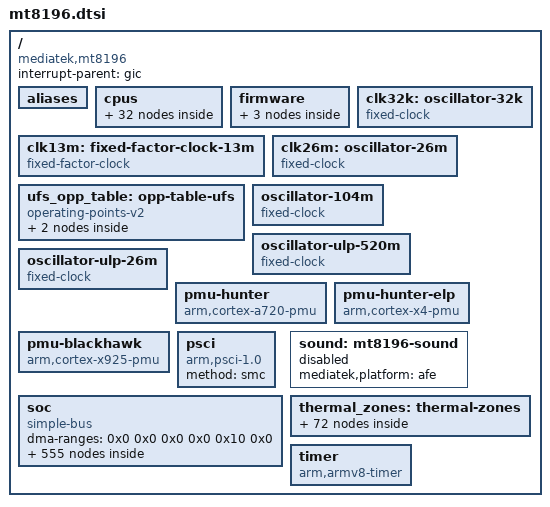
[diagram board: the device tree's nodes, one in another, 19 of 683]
// SPDX-License-Identifier: (GPL-2.0 OR MIT)
/*
 * Copyright (c) 2024 MediaTek Inc.
 * Copyright (c) 2025 Collabora Ltd
 *                    AngeloGioacchino Del Regno <angelogioacchino.delregno@collabora.com>
 */

/dts-v1/;
#include <dt-bindings/clock/mediatek,mt8196-clock.h>
#include <dt-bindings/reset/mediatek,mt8196-resets.h>
#include <dt-bindings/interrupt-controller/arm-gic.h>
#include <dt-bindings/interrupt-controller/irq.h>
#include <dt-bindings/phy/phy.h>
#include <dt-bindings/power/mediatek,mt8196-power.h>
#include <dt-bindings/reset/mediatek,mt8196-resets.h>
#include <dt-bindings/thermal/mediatek,lvts-thermal.h>
#include "mt8196-gce.h"
#include "mt8196-pinfunc.h"

/ {
	compatible = "mediatek,mt8196";
	interrupt-parent = <&gic>;
	#address-cells = <2>;
	#size-cells = <2>;

	aliases {
		blender0 = &ovl0_blender0;
		blender1 = &ovl0_blender1;
		blender2 = &ovl0_blender2;
		blender3 = &ovl0_blender3;
		blender4 = &ovl0_blender4;
		blender5 = &ovl0_blender5;
		blender6 = &ovl0_blender6;
		blender7 = &ovl0_blender7;
		blender8 = &ovl0_blender8;
		blender9 = &ovl0_blender9;
		blender10 = &ovl1_blender0;
		blender11 = &ovl1_blender1;
		blender12 = &ovl1_blender2;
		blender13 = &ovl1_blender3;
		blender14 = &ovl1_blender4;
		blender15 = &ovl1_blender5;
		blender16 = &ovl1_blender6;
		blender17 = &ovl1_blender7;
		blender18 = &ovl1_blender8;
		blender19 = &ovl1_blender9;
		ccorr0 = &ccorr0;
		ccorr1 = &ccorr1;
		ccorr2 = &ccorr2;
		ccorr3 = &ccorr3;
		dither0 = &dither0;
		dither1 = &dither1;
		dither2 = &disp1_dither2;
		dp-intf0 = &dp_intf0;
		dp-intf1 = &dp_intf1;
		dsc0 = &dsc0;
		dsc1 = &dsc1;
		dvo0 = &dvo0;
		exdma2 = &ovl0_exdma2;
		exdma3 = &ovl0_exdma3;
		exdma4 = &ovl0_exdma4;
		exdma5 = &ovl0_exdma5;
		exdma6 = &ovl0_exdma6;
		exdma7 = &ovl0_exdma7;
		exdma8 = &ovl0_exdma8;
		exdma9 = &ovl0_exdma9;
		exdma12 = &ovl1_exdma2;
		exdma13 = &ovl1_exdma3;
		exdma14 = &ovl1_exdma4;
		exdma15 = &ovl1_exdma5;
		exdma16 = &ovl1_exdma6;
		exdma17 = &ovl1_exdma7;
		exdma18 = &ovl1_exdma8;
		exdma19 = &ovl1_exdma9;
		gamma0 = &gamma0;
		gamma1 = &gamma1;
		i2c0 = &i2c0;
		i2c1 = &i2c1;
		i2c2 = &i2c2;
		i2c3 = &i2c3;
		i2c4 = &i2c4;
		i2c5 = &i2c5;
		i2c6 = &i2c6;
		i2c7 = &i2c7;
		i2c8 = &i2c8;
		i2c9 = &i2c9;
		i2c10 = &i2c10;
		i2c11 = &i2c11;
		i2c12 = &i2c12;
		i2c13 = &i2c13;
		i2c14 = &i2c14;
		mmc1 = &mmc1;
		mmc2 = &mmc2;
		mutex0 = &disp0_mutex;
		mutex1 = &disp1_mutex;
		mutex2 = &ovl0_mutex;
		mutex3 = &ovl1_mutex;
		outproc0 = &ovl0_outproc0;
		outproc1 = &ovl0_outproc1;
		outproc2 = &ovl0_outproc2;
		outproc3 = &ovl0_outproc3;
		outproc4 = &ovl0_outproc4;
		outproc5 = &ovl0_outproc5;
		outproc6 = &ovl1_outproc0;
		outproc7 = &ovl1_outproc1;
		outproc8 = &ovl1_outproc2;
		outproc9 = &ovl1_outproc3;
		outproc10 = &ovl1_outproc4;
		outproc11 = &ovl1_outproc5;
		postmask0 = &postmask0;
		postmask1 = &postmask1;
		resizer0 = &mdp_rsz0;
		resizer1 = &mdp_rsz1;
		resizer2 = &ovl0_rsz0;
		resizer4 = &ovl1_rsz0;
		spmi0 = &spmi0;
		spmi1 = &spmi1;
		tdshp0 = &tdshp0;
		tdshp1 = &tdshp1;
	};

	cpus {
		#address-cells = <1>;
		#size-cells = <0>;

		cpu0: cpu@0 {
			device_type = "cpu";
			compatible = "arm,cortex-a720";
			reg = <0x000>;
			enable-method = "psci";
			capacity-dmips-mhz = <714>;
			clock-frequency = <2100000000>;
			cpu-idle-states = <&cpuoff_l &clusteroff_l &s2idle>;
			performance-domains = <&performance 0>;
			i-cache-size = <65536>;
			i-cache-line-size = <64>;
			i-cache-sets = <256>;
			d-cache-size = <65536>;
			d-cache-line-size = <64>;
			d-cache-sets = <256>;
			next-level-cache = <&l2_0>;
			#cooling-cells = <2>;
		};

		cpu1: cpu@100 {
			device_type = "cpu";
			compatible = "arm,cortex-a720";
			reg = <0x100>;
			enable-method = "psci";
			capacity-dmips-mhz = <714>;
			clock-frequency = <2100000000>;
			cpu-idle-states = <&cpuoff_l &clusteroff_l &s2idle>;
			performance-domains = <&performance 0>;
			i-cache-size = <65536>;
			i-cache-line-size = <64>;
			i-cache-sets = <256>;
			d-cache-size = <65536>;
			d-cache-line-size = <64>;
			d-cache-sets = <256>;
			next-level-cache = <&l2_0>;
			#cooling-cells = <2>;
		};

		cpu2: cpu@200 {
			device_type = "cpu";
			compatible = "arm,cortex-a720";
			reg = <0x200>;
			enable-method = "psci";
			capacity-dmips-mhz = <714>;
			clock-frequency = <2100000000>;
			cpu-idle-states = <&cpuoff_l &clusteroff_l &s2idle>;
			performance-domains = <&performance 0>;
			i-cache-size = <65536>;
			i-cache-line-size = <64>;
			i-cache-sets = <256>;
			d-cache-size = <65536>;
			d-cache-line-size = <64>;
			d-cache-sets = <256>;
			next-level-cache = <&l2_0>;
			#cooling-cells = <2>;
		};

		cpu3: cpu@300 {
			device_type = "cpu";
			compatible = "arm,cortex-a720";
			reg = <0x300>;
			enable-method = "psci";
			capacity-dmips-mhz = <714>;
			clock-frequency = <2100000000>;
			cpu-idle-states = <&cpuoff_l &clusteroff_l &s2idle>;
			performance-domains = <&performance 0>;
			i-cache-size = <65536>;
			i-cache-line-size = <64>;
			i-cache-sets = <256>;
			d-cache-size = <65536>;
			d-cache-line-size = <64>;
			d-cache-sets = <256>;
			next-level-cache = <&l2_0>;
			#cooling-cells = <2>;
		};

		cpu4: cpu@400 {
			device_type = "cpu";
			compatible = "arm,cortex-x4";
			reg = <0x400>;
			enable-method = "psci";
			capacity-dmips-mhz = <835>;
			clock-frequency = <2800000000>;
			cpu-idle-states = <&cpuoff_m &clusteroff_m &s2idle>;
			performance-domains = <&performance 1>;
			i-cache-size = <65536>;
			i-cache-line-size = <64>;
			i-cache-sets = <256>;
			d-cache-size = <65536>;
			d-cache-line-size = <64>;
			d-cache-sets = <256>;
			next-level-cache = <&l2_1>;
			#cooling-cells = <2>;
		};

		cpu5: cpu@500 {
			device_type = "cpu";
			compatible = "arm,cortex-x4";
			reg = <0x500>;
			enable-method = "psci";
			capacity-dmips-mhz = <835>;
			clock-frequency = <2800000000>;
			cpu-idle-states = <&cpuoff_m &clusteroff_m &s2idle>;
			performance-domains = <&performance 1>;
			i-cache-size = <65536>;
			i-cache-line-size = <64>;
			i-cache-sets = <256>;
			d-cache-size = <65536>;
			d-cache-line-size = <64>;
			d-cache-sets = <256>;
			next-level-cache = <&l2_1>;
			#cooling-cells = <2>;
		};

		cpu6: cpu@600 {
			device_type = "cpu";
			compatible = "arm,cortex-x4";
			reg = <0x600>;
			enable-method = "psci";
			capacity-dmips-mhz = <835>;
			clock-frequency = <2800000000>;
			cpu-idle-states = <&cpuoff_m &clusteroff_m &s2idle>;
			performance-domains = <&performance 1>;
			i-cache-size = <65536>;
			i-cache-line-size = <64>;
			i-cache-sets = <256>;
			d-cache-size = <65536>;
			d-cache-line-size = <64>;
			d-cache-sets = <256>;
			next-level-cache = <&l2_1>;
			#cooling-cells = <2>;
		};

		cpu7: cpu@700 {
			device_type = "cpu";
			compatible = "arm,cortex-x925";
			reg = <0x700>;
			enable-method = "psci";
			capacity-dmips-mhz = <1024>;
			clock-frequency = <3600000000>;
			cpu-idle-states = <&cpuoff_b &clusteroff_b &s2idle>;
			performance-domains = <&performance 2>;
			i-cache-size = <65536>;
			i-cache-line-size = <64>;
			i-cache-sets = <256>;
			d-cache-size = <65536>;
			d-cache-line-size = <64>;
			d-cache-sets = <256>;
			next-level-cache = <&l2_2>;
			#cooling-cells = <2>;
		};

		cpu-map {
			cluster0 {
				core0 {
					cpu = <&cpu0>;
				};
				core1 {
					cpu = <&cpu1>;
				};
				core2 {
					cpu = <&cpu2>;
				};
				core3 {
					cpu = <&cpu3>;
				};
			};

			cluster1 {
				core0 {
					cpu = <&cpu4>;
				};
				core1 {
					cpu = <&cpu5>;
				};
				core2 {
					cpu = <&cpu6>;
				};
			};

			cluster2 {
				core0 {
					cpu = <&cpu7>;
				};
			};
		};

		idle-states {
			entry-method = "psci";

			cpuoff_l: cpuoff-l {
				compatible = "arm,idle-state";
				arm,psci-suspend-param = <0x00010000>;
				local-timer-stop;
				entry-latency-us = <97>;
				exit-latency-us = <252>;
				min-residency-us = <6710>;
			};

			cpuoff_m: cpuoff-m {
				compatible = "arm,idle-state";
				arm,psci-suspend-param = <0x00010000>;
				local-timer-stop;
				entry-latency-us = <53>;
				exit-latency-us = <143>;
				min-residency-us = <2120>;
			};

			cpuoff_b: cpuoff-b {
				compatible = "arm,idle-state";
				arm,psci-suspend-param = <0x00010000>;
				local-timer-stop;
				entry-latency-us = <40>;
				exit-latency-us = <107>;
				min-residency-us = <2580>;
			};

			clusteroff_l: clusteroff-l {
				compatible = "arm,idle-state";
				arm,psci-suspend-param = <0x01010001>;
				local-timer-stop;
				entry-latency-us = <109>;
				exit-latency-us = <325>;
				min-residency-us = <6710>;
			};

			clusteroff_m: clusteroff-m {
				compatible = "arm,idle-state";
				arm,psci-suspend-param = <0x01010001>;
				local-timer-stop;
				entry-latency-us = <59>;
				exit-latency-us = <188>;
				min-residency-us = <2120>;
			};

			clusteroff_b: clusteroff-b {
				compatible = "arm,idle-state";
				arm,psci-suspend-param = <0x01010001>;
				local-timer-stop;
				entry-latency-us = <43>;
				exit-latency-us = <138>;
				min-residency-us = <2580>;
			};

			s2idle: s2idle {
				compatible = "arm,idle-state";
				arm,psci-suspend-param = <0x020180ff>;
				local-timer-stop;
				entry-latency-us = <10000>;
				exit-latency-us = <10000>;
				min-residency-us = <6400000>;
			};
		};

		l2_0: l2-cache0 {
			compatible = "cache";
			cache-level = <2>;
			cache-size = <524288>;
			cache-line-size = <64>;
			cache-sets = <2048>;
			next-level-cache = <&l3_0>;
			cache-unified;
		};

		l2_1: l2-cache1 {
			compatible = "cache";
			cache-level = <2>;
			cache-size = <1048576>;
			cache-line-size = <64>;
			cache-sets = <4096>;
			next-level-cache = <&l3_0>;
			cache-unified;
		};

		l2_2: l2-cache2 {
			compatible = "cache";
			cache-level = <2>;
			cache-size = <2097152>;
			cache-line-size = <64>;
			cache-sets = <8192>;
			next-level-cache = <&l3_0>;
			cache-unified;
		};

		l3_0: l3-cache {
			compatible = "cache";
			cache-level = <3>;
			cache-size = <12582912>;
			cache-line-size = <64>;
			cache-sets = <49152>;
			cache-unified;
		};
	};

	firmware {
		optee {
			compatible = "linaro,optee-tz";
			method = "smc";
			interrupts-extended = <&gic GIC_SPI 955 IRQ_TYPE_LEVEL_HIGH 0>;
		};

		scmi {
			compatible = "arm,scmi";
			mboxes = <&tinysys_mbox_tx 0>, <&tinysys_mbox_rx 0>;
			mbox-names = "tx", "rx";
			shmem = <&scmi_tx_shmem>, <&scmi_rx_shmem>;
			#address-cells = <1>;
			#size-cells = <0>;

			scmi_tinysys: protocol@80 {
				reg = <0x80>;
			};
		};
	};

	clk13m: fixed-factor-clock-13m {
		compatible = "fixed-factor-clock";
		#clock-cells = <0>;
		clocks = <&clk26m>;
		clock-div = <2>;
		clock-mult = <1>;
		clock-output-names = "clk13m";
	};

	clk32k: oscillator-32k {
		compatible = "fixed-clock";
		#clock-cells = <0>;
		clock-frequency = <32000>;
		clock-output-names = "clk32k";
	};

	/* clk26m/104m may be turned off by firmware for deep sleep */
	clk26m: oscillator-26m {
		compatible = "fixed-clock";
		#clock-cells = <0>;
		clock-frequency = <26000000>;
		clock-output-names = "clk26m";
	};

	ufs_opp_table: opp-table-ufs {
		compatible = "operating-points-v2";

		opp-499200000 {
			opp-hz = /bits/ 64 <499200000>, /bits/ 64 <0>,
				 /bits/ 64 <0>, /bits/ 64 <0>, /bits/ 64 <0>,
				 /bits/ 64 <0>, /bits/ 64 <0>, /bits/ 64 <0>,
				 /bits/ 64 <0>, /bits/ 64 <0>, /bits/ 64 <0>,
				 /bits/ 64 <0>, /bits/ 64 <0>, /bits/ 64 <0>,
				 /bits/ 64 <0>, /bits/ 64 <0>;
		};

		opp-273000000 {
			opp-hz = /bits/ 64 <273000000>, /bits/ 64 <0>,
				 /bits/ 64 <0>, /bits/ 64 <0>, /bits/ 64 <0>,
				 /bits/ 64 <0>, /bits/ 64 <0>, /bits/ 64 <0>,
				 /bits/ 64 <0>, /bits/ 64 <0>, /bits/ 64 <0>,
				 /bits/ 64 <0>, /bits/ 64 <0>, /bits/ 64 <0>,
				 /bits/ 64 <0>, /bits/ 64 <0>;
		};
	};

	oscillator-104m {
		compatible = "fixed-clock";
		#clock-cells = <0>;
		clock-frequency = <104000000>;
		clock-output-names = "clk104m";
	};

	/* Ultra Low Power Oscillators used in deeper sleep states */
	oscillator-ulp-520m {
		compatible = "fixed-clock";
		#clock-cells = <0>;
		clock-frequency = <520000000>;
		clock-output-names = "ulposc";
	};

	oscillator-ulp-26m {
		compatible = "fixed-clock";
		#clock-cells = <0>;
		clock-frequency = <26000000>;
		clock-output-names = "ulposc3";
	};

	pmu-hunter {
		compatible = "arm,cortex-a720-pmu";
		interrupt-parent = <&gic>;
		interrupts = <GIC_PPI 7 IRQ_TYPE_LEVEL_HIGH &ppi_cluster0>;
	};

	pmu-hunter-elp {
		compatible = "arm,cortex-x4-pmu";
		interrupt-parent = <&gic>;
		interrupts = <GIC_PPI 7 IRQ_TYPE_LEVEL_HIGH &ppi_cluster1>;
	};

	pmu-blackhawk {
		compatible = "arm,cortex-x925-pmu";
		interrupt-parent = <&gic>;
		interrupts = <GIC_PPI 7 IRQ_TYPE_LEVEL_HIGH &ppi_cluster2>;
	};

	psci {
		compatible = "arm,psci-1.0";
		method = "smc";
	};

	soc {
		compatible = "simple-bus";
		#address-cells = <2>;
		#size-cells = <2>;
		ranges;
		dma-ranges = <0x0 0x0 0x0 0x0 0x10 0x0>;

		performance: performance-controller@c220400 {
			compatible = "mediatek,mt8196-cpufreq-hw";
			reg = <0 0xc220400 0 0x20>, <0 0xc2c0f20 0 0x120>,
			      <0 0xc2c1040 0 0x120>, <0 0xc2c1160 0 0x120>;
			#performance-domain-cells = <1>;
		};

		lvts_mcu: thermal-sensor@c230000 {
			compatible = "mediatek,mt8196-lvts-mcu";
			reg = <0 0x0c230000 0 0x1000>;
			interrupts = <GIC_SPI 104 IRQ_TYPE_LEVEL_HIGH 0>;
			clocks = <&clk26m>;
			nvmem-cells = <&lvts_efuse_data1 &lvts_efuse_data2
				       &lvts_efuse_data3 &lvts_efuse_data4>;
			nvmem-cell-names = "lvts-calib-data-1","lvts-calib-data-2",
					   "lvts-calib-data-3","lvts-calib-data-4";
			#thermal-sensor-cells = <1>;
		};

		gic: interrupt-controller@c400000 {
			compatible = "arm,gic-v3";
			reg = <0 0xc400000 0 0x40000>, <0 0xc440000 0 0x200000>;
			interrupt-parent = <&gic>;
			interrupts = <GIC_PPI 9 IRQ_TYPE_LEVEL_HIGH 0>;
			interrupt-controller;
			#interrupt-cells = <4>;
			#redistributor-regions = <1>;

			ppi-partitions {
				ppi_cluster0: interrupt-partition-0 {
					affinity = <&cpu0 &cpu1 &cpu2 &cpu3>;
				};

				ppi_cluster1: interrupt-partition-1 {
					affinity = <&cpu4 &cpu5 &cpu6>;
				};

				ppi_cluster2: interrupt-partition-2 {
					affinity = <&cpu7>;
				};
			};
		};

		topckgen: clock-controller@10000000 {
			compatible = "mediatek,mt8196-topckgen", "syscon";
			reg = <0 0x10000000 0 0x800>;
			mediatek,hardware-voter = <&scp_hwv>;
			#clock-cells = <1>;
		};

		apmixedsys: clock-controller@10000800 {
			compatible = "mediatek,mt8196-apmixedsys", "syscon";
			reg = <0 0x10000800 0 0x1000>;
			#clock-cells = <1>;
		};

		topckgen_gp2: clock-controller@1000c000 {
			compatible = "mediatek,mt8196-topckgen-gp2", "syscon";
			reg = <0 0x1000c000 0 0x800>;
			mediatek,hardware-voter = <&hfrpsys_hwv>;
			#clock-cells = <1>;
		};

		apmixedsys_gp2: clock-controller@1000c800 {
			compatible = "mediatek,mt8196-apmixedsys-gp2", "syscon";
			reg = <0 0x1000c800 0 0x1000>;
			#clock-cells = <1>;
		};

		infra_bus: bus@1002c000 {
			compatible = "simple-bus";
			reg = <0 0x1002c000 0 0x1000>;
			#address-cells = <2>;
			#size-cells = <2>;
			ranges;
			#access-controller-cells = <0>;
		};

		pio: pinctrl@1002d000 {
			compatible = "mediatek,mt8196-pinctrl";
			reg = <0 0x1002d000 0 0x1000>, <0 0x12000000 0 0x1000>,
			      <0 0x12020000 0 0x1000>, <0 0x12040000 0 0x1000>,
			      <0 0x12060000 0 0x1000>, <0 0x12820000 0 0x1000>,
			      <0 0x12840000 0 0x1000>, <0 0x12860000 0 0x1000>,
			      <0 0x13000000 0 0x1000>, <0 0x13020000 0 0x1000>,
			      <0 0x13040000 0 0x1000>, <0 0x130f0000 0 0x1000>,
			      <0 0x13110000 0 0x1000>, <0 0x13800000 0 0x1000>,
			      <0 0x13820000 0 0x1000>, <0 0x13860000 0 0x1000>,
			      <0 0x12080000 0 0x1000>, <0 0x12880000 0 0x1000>,
			      <0 0x13080000 0 0x1000>, <0 0x13880000 0 0x1000>,
			      <0 0x1c54a000 0 0x1000>;
			reg-names = "base", "rt", "rm1", "rm2", "rb", "bm1",
				    "bm2", "bm3", "lt", "lm1", "lm2", "lb1",
				    "lb2", "tm1", "tm2", "tm3", "eint0",
				    "eint1", "eint2", "eint3", "eint4";
			gpio-controller;
			#gpio-cells = <2>;
			gpio-ranges = <&pio 0 0 271>;
			interrupt-controller;
			interrupts = <GIC_SPI 396 IRQ_TYPE_LEVEL_HIGH 0>;
			#interrupt-cells = <2>;
			mediatek,rsel-resistance-in-si-unit;
		};

		i2c5: i2c@120a0000 {
			compatible = "mediatek,mt8196-i2c", "mediatek,mt8188-i2c";
			reg = <0 0x120a0000 0 0x20000>, <0 0x16400000 0 0x10000>;
			interrupts = <GIC_SPI 341 IRQ_TYPE_LEVEL_HIGH 0>;
			clocks = <&imp_iic_wrap_east CLK_IMPE_I2C5>,
				 <&pericfg_ao CLK_PERI_AO_AP_DMA_X32W_BCLK>;
			clock-names = "main", "dma";
			clock-div = <1>;
			#address-cells = <1>;
			#size-cells = <0>;
			status = "disabled";
		};

		imp_iic_wrap_east: clock-controller@120c0000 {
			compatible = "mediatek,mt8196-imp-iic-wrap-e", "syscon";
			reg = <0 0x120c0000 0 0x1000>;
			#clock-cells = <1>;
		};

		edp_phy: phy@130a0000 {
			compatible = "mediatek,mt8196-edp-phy";
			reg = <0 0x130a0000 0 0x1500>;
			#phy-cells = <0>;
			status = "disabled";

			nvmem-cells = <&edp_glb_bias_trim>, <&edp_clktx_impsel>,
				      <&edp_imp_ln0_pmos>, <&edp_imp_ln0_nmos>,
				      <&edp_imp_ln1_pmos>, <&edp_imp_ln1_nmos>,
				      <&edp_imp_ln2_pmos>, <&edp_imp_ln2_nmos>,
				      <&edp_imp_ln3_pmos>, <&edp_imp_ln3_nmos>;
			nvmem-cell-names = "rbias-trim", "impedance-txclk",
					   "impedance-lane0p", "impedance-lane0n",
					   "impedance-lane1p", "impedance-lane1n",
					   "impedance-lane2p", "impedance-lane2n",
					   "impedance-lane3p", "impedance-lane3n";

			power-domains = <&hpm_hwv MT8196_POWER_DOMAIN_DISP_EDPTX_DORMANT>;
		};

		mipi_tx_config0: dsi-phy@130b0000 {
			compatible = "mediatek,mt8196-mipi-tx";
			reg = <0 0x130b0000 0 0x1000>;
			clocks = <&clk26m>;
			clock-output-names = "mipi_tx0_pll";
			power-domains = <&hpm_hwv MT8196_POWER_DOMAIN_DSI_PHY0>;
			#clock-cells = <0>;
			#phy-cells = <0>;
			status = "disabled";
		};

		mipi_tx_config1: dsi-phy@130c0000 {
			compatible = "mediatek,mt8196-mipi-tx";
			reg = <0 0x130c0000 0 0x1000>;
			clocks = <&clk26m>;
			clock-output-names = "mipi_tx1_pll";
			power-domains = <&hpm_hwv MT8196_POWER_DOMAIN_DSI_PHY1>;
			#clock-cells = <0>;
			#phy-cells = <0>;
			status = "disabled";
		};

		mipi_tx_config2: dsi-phy@130d0000 {
			compatible = "mediatek,mt8196-mipi-tx";
			reg = <0 0x130d0000 0 0x1000>;
			clocks = <&clk26m>;
			clock-output-names = "mipi_tx2_pll";
			power-domains = <&hpm_hwv MT8196_POWER_DOMAIN_DSI_PHY2>;
			#clock-cells = <0>;
			#phy-cells = <0>;
			status = "disabled";
		};

		i2c0: i2c@13130000 {
			compatible = "mediatek,mt8196-i2c", "mediatek,mt8188-i2c";
			reg = <0 0x13130000 0 0x20000>, <0 0x16370000 0 0x10000>;
			interrupts = <GIC_SPI 342 IRQ_TYPE_LEVEL_HIGH 0>;
			clocks = <&imp_iic_wrap_west CLK_IMPW_I2C0>,
				 <&pericfg_ao CLK_PERI_AO_AP_DMA_X32W_BCLK>;
			clock-names = "main", "dma";
			clock-div = <1>;
			#address-cells = <1>;
			#size-cells = <0>;
			status = "disabled";
		};

		i2c3: i2c@13150000 {
			compatible = "mediatek,mt8196-i2c", "mediatek,mt8188-i2c";
			reg = <0 0x13150000 0 0x20000>, <0 0x163c0000 0 0x10000>;
			interrupts = <GIC_SPI 340 IRQ_TYPE_LEVEL_HIGH 0>;
			clocks = <&imp_iic_wrap_west CLK_IMPW_I2C3>,
				 <&pericfg_ao CLK_PERI_AO_AP_DMA_X32W_BCLK>;
			clock-names = "main", "dma";
			clock-div = <1>;
			#address-cells = <1>;
			#size-cells = <0>;
			status = "disabled";
		};

		i2c6: i2c@13170000 {
			compatible = "mediatek,mt8196-i2c", "mediatek,mt8188-i2c";
			reg = <0 0x13170000 0 0x20000>, <0 0x16410000 0 0x10000>;
			interrupts = <GIC_SPI 343 IRQ_TYPE_LEVEL_HIGH 0>;
			clocks = <&imp_iic_wrap_west CLK_IMPW_I2C6>,
				 <&pericfg_ao CLK_PERI_AO_AP_DMA_X32W_BCLK>;
			clock-names = "main", "dma";
			clock-div = <1>;
			#address-cells = <1>;
			#size-cells = <0>;
			status = "disabled";
		};

		i2c10: i2c@13190000 {
			compatible = "mediatek,mt8196-i2c", "mediatek,mt8188-i2c";
			reg = <0 0x13190000 0 0x20000>,
			      <0 0x164b0000 0 0x10000>;
			interrupts = <GIC_SPI 344 IRQ_TYPE_LEVEL_HIGH 0>;
			clocks = <&imp_iic_wrap_west CLK_IMPW_I2C10>,
				 <&pericfg_ao CLK_PERI_AO_AP_DMA_X32W_BCLK>;
			clock-names = "main", "dma";
			clock-div = <1>;
			#address-cells = <1>;
			#size-cells = <0>;
			status = "disabled";
		};

		imp_iic_wrap_west: clock-controller@131b0000 {
			compatible = "mediatek,mt8196-imp-iic-wrap-w", "syscon";
			reg = <0 0x131b0000 0 0x1000>;
			#clock-cells = <1>;
		};

		efuse: efuse@13260000 {
			compatible = "mediatek,mt8196-efuse", "mediatek,efuse";
			reg = <0 0x13260000 0 0x1000>;
			#address-cells = <1>;
			#size-cells = <1>;

			edp_clktx_impsel: edp-dphy-impedance-clk@1b9 {
				reg = <0x1b9 0x1>;
				bits = <1 4>;
			};

			edp_imp_ln3_nmos: edp-dphy-imp-ln3-nmos@1c0,1 {
				reg = <0x1c0 0x1>;
				bits = <0 4>;
			};

			edp_imp_ln3_pmos: edp-dphy-imp-ln3-pmos@1c0,2 {
				reg = <0x1c0 0x1>;
				bits = <4 4>;
			};

			edp_imp_ln2_nmos: edp-dphy-imp-ln2-nmos@1c1,1 {
				reg = <0x1c1 0x1>;
				bits = <0 4>;
			};

			edp_imp_ln2_pmos: edp-dphy-imp-ln2-pmos@1c1,2 {
				reg = <0x1c1 0x1>;
				bits = <4 4>;
			};

			edp_imp_ln1_nmos: edp-dphy-imp-ln1-nmos@1c2,1 {
				reg = <0x1c2 0x1>;
				bits = <0 4>;
			};

			edp_imp_ln1_pmos: edp-dphy-imp-ln1-pmos@1c2,2 {
				reg = <0x1c2 0x1>;
				bits = <4 4>;
			};

			edp_imp_ln0_nmos: edp-dphy-imp-ln0-nmos@1c3,1 {
				reg = <0x1c3 0x1>;
				bits = <0 4>;
			};

			edp_imp_ln0_pmos: edp-dphy-imp-ln0-pmos@1c3,2 {
				reg = <0x1c3 0x1>;
				bits = <4 4>;
			};

			edp_glb_bias_trim: edp-dphy-rbias@1c7 {
				reg = <0x1c7 0x1>;
				bits = <3 5>;
			};

			lvts_efuse_data1: lvts1_calib@334 {
				reg = <0x334 0xc>;
			};

			lvts_efuse_data2: lvts2_calib@340 {
				reg = <0x340 0x14>;
			};

			lvts_efuse_data3: lvts3_calib@354 {
				reg = <0x354 0x20>;
			};

			lvts_efuse_data4: lvts4_calib@388 {
				reg = <0x388 0x20>;
			};
		};

		i2c1: i2c@13930000 {
			compatible = "mediatek,mt8196-i2c", "mediatek,mt8188-i2c";
			reg = <0 0x13930000 0 0x80000>, <0 0x16380000 0 0x10000>;
			interrupts = <GIC_SPI 345 IRQ_TYPE_LEVEL_HIGH 0>;
			clocks = <&imp_iic_wrap_north CLK_IMPN_I2C1>,
				 <&pericfg_ao CLK_PERI_AO_AP_DMA_X32W_BCLK>;
			clock-names = "main", "dma";
			clock-div = <1>;
			#address-cells = <1>;
			#size-cells = <0>;
			status = "disabled";
		};

		i2c2: i2c@139b0000 {
			compatible = "mediatek,mt8196-i2c", "mediatek,mt8188-i2c";
			reg = <0 0x139b0000 0 0x80000>, <0 0x16390000 0 0x30000>;
			interrupts = <GIC_SPI 346 IRQ_TYPE_LEVEL_HIGH 0>;
			clocks = <&imp_iic_wrap_north CLK_IMPN_I2C2>,
				 <&pericfg_ao CLK_PERI_AO_AP_DMA_X32W_BCLK>;
			clock-names = "main", "dma";
			clock-div = <1>;
			#address-cells = <1>;
			#size-cells = <0>;
			status = "disabled";
		};

		i2c4: i2c@13a30000 {
			compatible = "mediatek,mt8196-i2c", "mediatek,mt8188-i2c";
			reg = <0 0x13a30000 0 0x80000>, <0 0x163d0000 0 0x30000>;
			interrupts = <GIC_SPI 347 IRQ_TYPE_LEVEL_HIGH 0>;
			clocks = <&imp_iic_wrap_north CLK_IMPN_I2C4>,
				 <&pericfg_ao CLK_PERI_AO_AP_DMA_X32W_BCLK>;
			clock-names = "main", "dma";
			clock-div = <1>;
			#address-cells = <1>;
			#size-cells = <0>;
			status = "disabled";
		};

		i2c7: i2c@13ab0000 {
			compatible = "mediatek,mt8196-i2c", "mediatek,mt8188-i2c";
			reg = <0 0x13ab0000 0 0x80000>, <0 0x16420000 0 0x30000>;
			interrupts = <GIC_SPI 348 IRQ_TYPE_LEVEL_HIGH 0>;
			clocks = <&imp_iic_wrap_north CLK_IMPN_I2C7>,
				 <&pericfg_ao CLK_PERI_AO_AP_DMA_X32W_BCLK>;
			clock-names = "main", "dma";
			clock-div = <1>;
			#address-cells = <1>;
			#size-cells = <0>;
			status = "disabled";
		};

		i2c8: i2c@13b30000 {
			compatible = "mediatek,mt8196-i2c", "mediatek,mt8188-i2c";
			reg = <0 0x13b30000 0 0x80000>, <0 0x16450000 0 0x30000>;
			interrupts = <GIC_SPI 349 IRQ_TYPE_LEVEL_HIGH 0>;
			clocks = <&imp_iic_wrap_north CLK_IMPN_I2C8>,
				 <&pericfg_ao CLK_PERI_AO_AP_DMA_X32W_BCLK>;
			clock-names = "main", "dma";
			clock-div = <1>;
			#address-cells = <1>;
			#size-cells = <0>;
			status = "disabled";
		};

		i2c9: i2c@13bb0000 {
			compatible = "mediatek,mt8196-i2c", "mediatek,mt8188-i2c";
			reg = <0 0x13bb0000 0 0x80000>, <0 0x16480000 0 0x30000>;
			interrupts = <GIC_SPI 350 IRQ_TYPE_LEVEL_HIGH 0>;
			clocks = <&imp_iic_wrap_north CLK_IMPN_I2C9>,
				 <&pericfg_ao CLK_PERI_AO_AP_DMA_X32W_BCLK>;
			clock-names = "main", "dma";
			clock-div = <1>;
			#address-cells = <1>;
			#size-cells = <0>;
			status = "disabled";
		};

		imp_iic_wrap_north: clock-controller@13c30000 {
			compatible = "mediatek,mt8196-imp-iic-wrap-n", "syscon";
			reg = <0 0x13c30000 0 0x1000>;
			mediatek,hardware-voter = <&scp_hwv>;
			#clock-cells = <1>;
		};

		lvts_ap: thermal-sensor@14414000 {
			compatible = "mediatek,mt8196-lvts-ap";
			reg = <0 0x14414000 0 0x1000>;
			interrupts = <GIC_SPI 358 IRQ_TYPE_LEVEL_HIGH 0>;
			clocks = <&clk26m>;
			nvmem-cells = <&lvts_efuse_data1 &lvts_efuse_data2
				       &lvts_efuse_data3 &lvts_efuse_data4>;
			nvmem-cell-names = "lvts-calib-data-1","lvts-calib-data-2",
					   "lvts-calib-data-3","lvts-calib-data-4";
			#thermal-sensor-cells = <1>;
		};

		scp_hwv: system-controller@14500000 {
			compatible = "mediatek,mt8196-scpsys", "syscon", "simple-mfd";
			reg = <0 0x14500000 0 0x3000>;

			/* SCP Power Manager with Hardware Voter */
			spm_hwv: power-controller {
				compatible = "mediatek,mt8196-hwv-scp-power-controller";
				#address-cells = <1>;
				#size-cells = <0>;
				#power-domain-cells = <1>;

				/* SCPSYS hardware voter power domains */
				power-domain@MT8196_POWER_DOMAIN_MM_PROC_DORMANT {
					reg = <MT8196_POWER_DOMAIN_MM_PROC_DORMANT>;
					#power-domain-cells = <0>;
				};

				power-domain@MT8196_POWER_DOMAIN_SSR {
					reg = <MT8196_POWER_DOMAIN_SSR>;
					#power-domain-cells = <0>;
				};
			};
		};

		uart0: serial@16000000 {
			compatible = "mediatek,mt8196-uart", "mediatek,mt6577-uart";
			reg = <0 0x16000000 0 0x1000>;
			interrupts = <GIC_SPI 311 IRQ_TYPE_LEVEL_HIGH 0>;
			clocks = <&clk26m>, <&pericfg_ao CLK_PERI_AO_UART0_BCLK>;
			clock-names = "baud", "bus";
			dmas = <&apdma 0>, <&apdma 1>;
			dma-names = "tx", "rx";
			status = "disabled";
		};

		uart1: serial@16010000 {
			compatible = "mediatek,mt8196-uart", "mediatek,mt6577-uart";
			reg = <0 0x16010000 0 0x1000>;
			interrupts = <GIC_SPI 312 IRQ_TYPE_LEVEL_HIGH 0>;
			clocks = <&clk26m>, <&pericfg_ao CLK_PERI_AO_UART1_BCLK>;
			clock-names = "baud", "bus";
			dmas = <&apdma 2>, <&apdma 3>;
			dma-names = "tx", "rx";
			status = "disabled";
		};

		uart2: serial@16020000 {
			compatible = "mediatek,mt8196-uart", "mediatek,mt6577-uart";
			reg = <0 0x16020000 0 0x1000>;
			interrupts = <GIC_SPI 313 IRQ_TYPE_LEVEL_HIGH 0>;
			clocks = <&clk26m>, <&pericfg_ao CLK_PERI_AO_UART2_BCLK>;
			clock-names = "baud", "bus";
			dmas = <&apdma 4>, <&apdma 5>;
			dma-names = "tx", "rx";
			status = "disabled";
		};

		/* UART3 is at 0x1604000 but it is special and not yet supported */

		uart4: serial@16040000 {
			compatible = "mediatek,mt8196-uart", "mediatek,mt6577-uart";
			reg = <0 0x16040000 0 0x1000>;
			interrupts = <GIC_SPI 315 IRQ_TYPE_LEVEL_HIGH 0>;
			clocks = <&clk26m>, <&pericfg_ao CLK_PERI_AO_UART4_BCLK>;
			clock-names = "baud", "bus";
			dmas = <&apdma 8>, <&apdma 9>;
			dma-names = "tx", "rx";
			status = "disabled";
		};

		uart5: serial@16050000 {
			compatible = "mediatek,mt8196-uart", "mediatek,mt6577-uart";
			reg = <0 0x16050000 0 0x1000>;
			interrupts = <GIC_SPI 316 IRQ_TYPE_LEVEL_HIGH 0>;
			clocks = <&clk26m>, <&pericfg_ao CLK_PERI_AO_UART5_BCLK>;
			clock-names = "baud", "bus";
			dmas = <&apdma 10>, <&apdma 11>;
			dma-names = "tx", "rx";
			status = "disabled";
		};

		disp_pwm0: pwm@160b0000 {
			compatible = "mediatek,mt8196-disp-pwm", "mediatek,mt8183-disp-pwm";
			reg = <0 0x160b0000 0 0x1000>;
			interrupts = <GIC_SPI 254 IRQ_TYPE_LEVEL_HIGH 0>;
			clocks = <&topckgen CLK_TOP_DISP_PWM>, <&clk26m>;
			clock-names = "main", "mm";
			#pwm-cells = <2>;
			status = "disabled";
		};

		disp_pwm1: pwm@160c0000 {
			compatible = "mediatek,mt8196-disp-pwm", "mediatek,mt8183-disp-pwm";
			reg = <0 0x160c0000 0 0x1000>;
			clocks = <&topckgen CLK_TOP_DISP_PWM>;
			clock-names = "main";
			#pwm-cells = <2>;
			status = "disabled";
		};

		disp_pwm2: pwm@160d0000 {
			compatible = "mediatek,mt8196-disp-pwm", "mediatek,mt8183-disp-pwm";
			reg = <0 0x160d0000 0 0x1000>;
			clocks = <&topckgen CLK_TOP_DISP_PWM>;
			clock-names = "main";
			#pwm-cells = <2>;
			status = "disabled";
		};

		disp_pwm3: pwm@160e0000 {
			compatible = "mediatek,mt8196-disp-pwm", "mediatek,mt8183-disp-pwm";
			reg = <0 0x160e0000 0 0x1000>;
			clocks = <&topckgen CLK_TOP_DISP_PWM>;
			clock-names = "main";
			#pwm-cells = <2>;
			status = "disabled";
		};

		disp_pwm4: pwm@160f0000 {
			compatible = "mediatek,mt8196-disp-pwm", "mediatek,mt8183-disp-pwm";
			reg = <0 0x160f0000 0 0x1000>;
			clocks = <&topckgen CLK_TOP_DISP_PWM>;
			clock-names = "main";
			#pwm-cells = <2>;
			status = "disabled";
		};

		spi0: spi@16110000 {
			compatible = "mediatek,mt8196-spi", "mediatek,mt6991-spi";
			reg = <0 0x16110000 0 0x100>;
			interrupts = <GIC_SPI 303 IRQ_TYPE_LEVEL_HIGH 0>;
			clocks = <&topckgen CLK_TOP_UNIVPLL_D6_D2>,
				 <&topckgen CLK_TOP_SPI0_BCLK>,
				 <&pericfg_ao CLK_PERI_AO_SPI0_BCLK>;
			clock-names = "parent-clk", "sel-clk", "spi-clk";
			#address-cells = <1>;
			#size-cells = <0>;
			status = "disabled";
		};

		spi1: spi@16130000 {
			compatible = "mediatek,mt8196-spi", "mediatek,mt6991-spi";
			reg = <0 0x16130000 0 0x100>;
			interrupts = <GIC_SPI 304 IRQ_TYPE_LEVEL_HIGH 0>;
			clocks = <&topckgen CLK_TOP_UNIVPLL_D6_D2>,
				 <&topckgen CLK_TOP_SPI1_BCLK>,
				 <&pericfg_ao CLK_PERI_AO_SPI1_BCLK>;
			clock-names = "parent-clk", "sel-clk", "spi-clk";
			#address-cells = <1>;
			#size-cells = <0>;
			status = "disabled";
		};

		spi2: spi@16150000 {
			compatible = "mediatek,mt8196-spi", "mediatek,mt6991-spi";
			reg = <0 0x16150000 0 0x100>;
			interrupts = <GIC_SPI 305 IRQ_TYPE_LEVEL_HIGH 0>;
			clocks = <&topckgen CLK_TOP_UNIVPLL_D6_D2>,
				 <&topckgen CLK_TOP_SPI2_BCLK>,
				 <&pericfg_ao CLK_PERI_AO_SPI2_BCLK>;
			clock-names = "parent-clk", "sel-clk", "spi-clk";
			#address-cells = <1>;
			#size-cells = <0>;
			status = "disabled";
		};

		spi3: spi@16170000 {
			compatible = "mediatek,mt8196-spi", "mediatek,mt6991-spi";
			reg = <0 0x16170000 0 0x100>;
			interrupts = <GIC_SPI 306 IRQ_TYPE_LEVEL_HIGH 0>;
			clocks = <&topckgen CLK_TOP_UNIVPLL_D6_D2>,
				 <&topckgen CLK_TOP_SPI3_BCLK>,
				 <&pericfg_ao CLK_PERI_AO_SPI3_BCLK>;
			clock-names = "parent-clk", "sel-clk", "spi-clk";
			#address-cells = <1>;
			#size-cells = <0>;
			status = "disabled";
		};

		spi4: spi@16190000 {
			compatible = "mediatek,mt8196-spi", "mediatek,mt6991-spi";
			reg = <0 0x16190000 0 0x100>;
			interrupts = <GIC_SPI 307 IRQ_TYPE_LEVEL_HIGH 0>;
			clocks = <&topckgen CLK_TOP_UNIVPLL_D6_D2>,
				 <&topckgen CLK_TOP_SPI4_BCLK>,
				 <&pericfg_ao CLK_PERI_AO_SPI4_BCLK>;
			clock-names = "parent-clk", "sel-clk", "spi-clk";
			#address-cells = <1>;
			#size-cells = <0>;
			status = "disabled";
		};

		spi5: spi@161b0000 {
			compatible = "mediatek,mt8196-spi", "mediatek,mt6991-spi";
			reg = <0 0x161b0000 0 0x100>;
			interrupts = <GIC_SPI 308 IRQ_TYPE_LEVEL_HIGH 0>;
			clocks = <&topckgen CLK_TOP_UNIVPLL_D6_D2>,
				 <&topckgen CLK_TOP_SPI5_BCLK>,
				 <&pericfg_ao CLK_PERI_AO_SPI5_BCLK>;
			clock-names = "parent-clk", "sel-clk", "spi-clk";
			#address-cells = <1>;
			#size-cells = <0>;
			status = "disabled";
		};

		spi6: spi@161d0000 {
			compatible = "mediatek,mt8196-spi", "mediatek,mt6991-spi";
			reg = <0 0x161d0000 0 0x100>;
			interrupts = <GIC_SPI 309 IRQ_TYPE_LEVEL_HIGH 0>;
			clocks = <&topckgen CLK_TOP_UNIVPLL_D6_D2>,
				 <&topckgen CLK_TOP_SPI6_BCLK>,
				 <&pericfg_ao CLK_PERI_AO_SPI6_BCLK>;
			clock-names = "parent-clk", "sel-clk", "spi-clk";
			#address-cells = <1>;
			#size-cells = <0>;
			status = "disabled";
		};

		spi7: spi@161f0000 {
			compatible = "mediatek,mt8196-spi", "mediatek,mt6991-spi";
			reg = <0 0x161f0000 0 0x100>;
			interrupts = <GIC_SPI 310 IRQ_TYPE_LEVEL_HIGH 0>;
			clocks = <&topckgen CLK_TOP_UNIVPLL_D6_D2>,
				 <&topckgen CLK_TOP_SPI7_BCLK>,
				 <&pericfg_ao CLK_PERI_AO_SPI7_BCLK>;
			clock-names = "parent-clk", "sel-clk", "spi-clk";
			#address-cells = <1>;
			#size-cells = <0>;
			status = "disabled";
		};

		i2c11: i2c@16200000 {
			compatible = "mediatek,mt8196-i2c", "mediatek,mt8188-i2c";
			reg = <0 0x16200000 0 0x40000>, <0 0x164c0000 0 0x10000>;
			interrupts = <GIC_SPI 270 IRQ_TYPE_LEVEL_HIGH 0>;
			clocks = <&imp_iic_wrap_center CLK_IMPC_I2C11>,
				 <&pericfg_ao CLK_PERI_AO_AP_DMA_X32W_BCLK>;
			clock-names = "main", "dma";
			clock-div = <1>;
			#address-cells = <1>;
			#size-cells = <0>;
			status = "disabled";
		};

		i2c12: i2c@16240000 {
			compatible = "mediatek,mt8196-i2c", "mediatek,mt8188-i2c";
			reg = <0 0x16240000 0 0x40000>, <0 0x164d0000 0 0x20000>;
			interrupts = <GIC_SPI 271 IRQ_TYPE_LEVEL_HIGH 0>;
			clocks = <&imp_iic_wrap_center CLK_IMPC_I2C12>,
				 <&pericfg_ao CLK_PERI_AO_AP_DMA_X32W_BCLK>;
			clock-names = "main", "dma";
			clock-div = <1>;
			#address-cells = <1>;
			#size-cells = <0>;
			status = "disabled";
		};

		i2c13: i2c@16280000 {
			compatible = "mediatek,mt8196-i2c", "mediatek,mt8188-i2c";
			reg = <0 0x16280000 0 0x40000>, <0 0x164f0000 0 0x10000>;
			interrupts = <GIC_SPI 272 IRQ_TYPE_LEVEL_HIGH 0>;
			clocks = <&imp_iic_wrap_center CLK_IMPC_I2C13>,
				 <&pericfg_ao CLK_PERI_AO_AP_DMA_X32W_BCLK>;
			clock-names = "main", "dma";
			clock-div = <1>;
			#address-cells = <1>;
			#size-cells = <0>;
			status = "disabled";
		};

		i2c14: i2c@162c0000 {
			compatible = "mediatek,mt8196-i2c", "mediatek,mt8188-i2c";
			reg = <0 0x162c0000 0 0x40000>,<0 0x16500000 0 0x10000>;
			interrupts = <GIC_SPI 900 IRQ_TYPE_LEVEL_HIGH 0>;
			clocks = <&imp_iic_wrap_center CLK_IMPC_I2C14>,
				 <&pericfg_ao CLK_PERI_AO_AP_DMA_X32W_BCLK>;
			clock-names = "main", "dma";
			clock-div = <1>;
			#address-cells = <1>;
			#size-cells = <0>;
			status = "disabled";
		};

		imp_iic_wrap_center: clock-controller@16300000 {
			compatible = "mediatek,mt8196-imp-iic-wrap-c", "syscon";
			reg = <0 0x16300000 0 0x1000>;
			#clock-cells = <1>;
		};

		mmc1: mmc@16310000 {
			compatible = "mediatek,mt8196-mmc";
			reg = <0 0x16310000 0 0x1000>, <0 0x12a10000 0 0x1000>;
			interrupts = <GIC_SPI 267 IRQ_TYPE_LEVEL_HIGH 0>;
			clocks = <&topckgen CLK_TOP_MSDC30_1>,
				 <&pericfg_ao CLK_PERI_AO_MSDC1_HCLK_WRAP>,
				 <&pericfg_ao CLK_PERI_AO_MSDC1_MSDC_SRC>;
			clock-names = "source", "hclk", "source_cg";
			status = "disabled";
		};

		mmc2: mmc@16320000 {
			compatible = "mediatek,mt8196-mmc";
			reg = <0 0x16320000 0 0x1000>, <0 0x138a0000 0 0x1000>;
			interrupts = <GIC_SPI 268 IRQ_TYPE_LEVEL_HIGH 0>;
			clocks = <&topckgen CLK_TOP_MSDC30_2>,
				 <&pericfg_ao CLK_PERI_AO_MSDC2_HCLK_WRAP>,
				 <&pericfg_ao CLK_PERI_AO_MSDC2_MSDC_SRC>;
			clock-names = "source", "hclk", "source_cg";
			status = "disabled";
		};

		pwm@16330000 {
			compatible = "mediatek,mt8196-pwm", "mediatek,mt6991-pwm";
			reg = <0 0x16330000 0 0x1000>;
			interrupts = <GIC_SPI 319 IRQ_TYPE_LEVEL_HIGH 0>;
			clocks = <&pericfg_ao CLK_PERI_AO_PWM_X16W_HCLK>,
				 <&pericfg_ao CLK_PERI_AO_PWM_X16W_BCLK>,
				 <&pericfg_ao CLK_PERI_AO_PWM_PWM_BCLK0>,
				 <&pericfg_ao CLK_PERI_AO_PWM_PWM_BCLK1>,
				 <&pericfg_ao CLK_PERI_AO_PWM_PWM_BCLK2>,
				 <&pericfg_ao CLK_PERI_AO_PWM_PWM_BCLK3>;
			clock-names = "top", "main", "pwm1", "pwm2", "pwm3", "pwm4";
			status = "disabled";
		};

		nor_flash: spi@16340000 {
			compatible = "mediatek,mt8196-nor", "mediatek,mt8186-nor";
			reg = <0 0x16340000 0 0x1000>;
			clocks = <&topckgen CLK_TOP_SFLASH>,
				 <&pericfg_ao CLK_PERI_AO_FLASHIF_FLASH>,
				 <&pericfg_ao CLK_PERI_AO_FLASHIF_AXI>,
				 <&pericfg_ao CLK_PERI_AO_FLASHIF_BCLK>;
			clock-names = "spi", "sf", "axi", "axi_s";
			assigned-clocks = <&topckgen CLK_TOP_SFLASH>;
			assigned-clock-parents = <&topckgen CLK_TOP_UNIVPLL_D6_D8>;
			interrupts = <GIC_SPI 269 IRQ_TYPE_LEVEL_HIGH 0>;
			#address-cells = <1>;
			#size-cells = <0>;
			status = "disabled";
		};

		eth0: ethernet@165b0000 {
			compatible = "mediatek,mt8196-gmac", "snps,dwmac-5.10a";
			reg = <0 0x165b0000 0 0x4000>;
			interrupts = <GIC_SPI 913 IRQ_TYPE_LEVEL_HIGH 0>;
			interrupt-names = "macirq";
			assigned-clocks = <&topckgen CLK_TOP_GMAC_125M>,
					  <&topckgen CLK_TOP_GMAC_62P4M_PTP>,
					  <&topckgen CLK_TOP_GMAC_RMII>;
			assigned-clock-parents = <&topckgen CLK_TOP_NET1PLL_D5>,
						 <&topckgen CLK_TOP_UNIVPLL_D5_D8>,
						 <&topckgen CLK_TOP_NET1PLL_D5_D5>;
			clock-names = "mac_main",
				      "ptp_ref",
				      "rmii_internal";
			clocks = <&topckgen CLK_TOP_GMAC_125M>,
				 <&topckgen CLK_TOP_GMAC_62P4M_PTP>,
				 <&topckgen CLK_TOP_GMAC_RMII>;
			power-domains = <&spm MT8196_POWER_DOMAIN_PERI_ETHER>;
			mediatek,pericfg = <&pericfg_ao 0x300>;
			snps,axi-config = <&stmmac_axi_setup_mac0>;
			snps,mtl-rx-config = <&mtl_rx_setup_mac0>;
			snps,mtl-tx-config = <&mtl_tx_setup_mac0>;
			snps,txpbl = <16>;
			snps,rxpbl = <16>;
			snps,clk-csr = <0>;
			status = "disabled";

			stmmac_axi_setup_mac0: stmmac-axi-config-mac0 {
				snps,wr-osr-lmt = <0x7>;
				snps,rd-osr-lmt = <0x7>;
				snps,blen = <0 0 0 0 16 8 4>;
			};

			mtl_rx_setup_mac0: rx-queues-config-mac0 {
				snps,rx-queues-to-use = <4>;
				snps,rx-sched-sp;

				queue0 {
					snps,dcb-algorithm;
					snps,map-to-dma-channel = <0x0>;
				};

				queue1 {
					snps,dcb-algorithm;
					snps,map-to-dma-channel = <0x0>;
				};

				queue2 {
					snps,dcb-algorithm;
					snps,map-to-dma-channel = <0x0>;
				};

				queue3 {
					snps,dcb-algorithm;
					snps,map-to-dma-channel = <0x0>;
				};
			};

			mtl_tx_setup_mac0: tx-queues-config-mac0 {
				snps,tx-queues-to-use = <4>;
				snps,tx-sched-wrr;

				queue0 {
					snps,weight = <0x10>;
					snps,dcb-algorithm;
					snps,priority = <0x0>;
				};

				queue1 {
					snps,weight = <0x11>;
					snps,dcb-algorithm;
					snps,priority = <0x1>;
				};

				queue2 {
					snps,weight = <0x12>;
					snps,dcb-algorithm;
					snps,priority = <0x2>;
				};

				queue3 {
					snps,weight = <0x13>;
					snps,dcb-algorithm;
					snps,priority = <0x3>;
				};
			};
		};

		eth1: ethernet@165c0000 {
			compatible = "mediatek,mt8196-gmac", "snps,dwmac-5.10a";
			reg = <0 0x165c0000 0 0x4000>;
			interrupts = <GIC_SPI 920 IRQ_TYPE_LEVEL_HIGH 0>;
			interrupt-names = "macirq";
			assigned-clocks = <&topckgen CLK_TOP_GMAC_125M>,
					  <&topckgen CLK_TOP_GMAC_62P4M_PTP>,
					  <&topckgen CLK_TOP_GMAC_RMII>;
			assigned-clock-parents = <&topckgen CLK_TOP_NET1PLL_D5>,
						 <&topckgen CLK_TOP_UNIVPLL_D5_D8>,
						 <&topckgen CLK_TOP_NET1PLL_D5_D5>;
			clock-names = "mac_main",
				      "ptp_ref",
				      "rmii_internal";
			clocks = <&topckgen CLK_TOP_GMAC_125M>,
				 <&topckgen CLK_TOP_GMAC_62P4M_PTP>,
				 <&topckgen CLK_TOP_GMAC_RMII>;
			power-domains = <&spm MT8196_POWER_DOMAIN_PERI_ETHER>;
			mediatek,pericfg = <&pericfg_ao 0x310>;
			snps,axi-config = <&stmmac_axi_setup_mac1>;
			snps,mtl-rx-config = <&mtl_rx_setup_mac1>;
			snps,mtl-tx-config = <&mtl_tx_setup_mac1>;
			snps,txpbl = <16>;
			snps,rxpbl = <16>;
			snps,clk-csr = <0>;
			status = "disabled";

			stmmac_axi_setup_mac1: stmmac-axi-config-mac1 {
				snps,wr-osr-lmt = <0x7>;
				snps,rd-osr-lmt = <0x7>;
				snps,blen = <0 0 0 0 16 8 4>;
			};

			mtl_rx_setup_mac1: rx-queues-config-mac1 {
				snps,rx-queues-to-use = <4>;
				snps,rx-sched-sp;

				queue0 {
					snps,dcb-algorithm;
					snps,map-to-dma-channel = <0x0>;
				};

				queue1 {
					snps,dcb-algorithm;
					snps,map-to-dma-channel = <0x0>;
				};

				queue2 {
					snps,dcb-algorithm;
					snps,map-to-dma-channel = <0x0>;
				};

				queue3 {
					snps,dcb-algorithm;
					snps,map-to-dma-channel = <0x0>;
				};
			};

			mtl_tx_setup_mac1: tx-queues-config-mac1 {
				snps,tx-queues-to-use = <4>;
				snps,tx-sched-wrr;

				queue0 {
					snps,weight = <0x10>;
					snps,dcb-algorithm;
					snps,priority = <0x0>;
				};

				queue1 {
					snps,weight = <0x11>;
					snps,dcb-algorithm;
					snps,priority = <0x1>;
				};

				queue2 {
					snps,weight = <0x12>;
					snps,dcb-algorithm;
					snps,priority = <0x2>;
				};

				queue3 {
					snps,weight = <0x13>;
					snps,dcb-algorithm;
					snps,priority = <0x3>;
				};
			};
		};

		pericfg_ao: clock-controller@16640000 {
			compatible = "mediatek,mt8196-pericfg-ao", "syscon";
			reg = <0 0x16640000 0 0x1000>;
			mediatek,hardware-voter = <&scp_hwv>;
			#clock-cells = <1>;
		};

		apdma: dma-controller@16510000 {
			compatible = "mediatek,mt8196-uart-dma", "mediatek,mt6985-uart-dma";
			reg = <0 0x16510000 0 0x80>, <0 0x16510080 0 0x80>,
			      <0 0x16520000 0 0x80>, <0 0x16520080 0 0x80>,
			      <0 0x16530000 0 0x80>, <0 0x16530080 0 0x80>,
			      <0 0x16540000 0 0x80>, <0 0x16540080 0 0x80>,
			      <0 0x16550000 0 0x80>, <0 0x16550080 0 0x80>,
			      <0 0x16560000 0 0x80>, <0 0x16560080 0 0x80>;
			interrupts = <GIC_SPI 299 IRQ_TYPE_LEVEL_HIGH 0>,
				     <GIC_SPI 300 IRQ_TYPE_LEVEL_HIGH 0>,
				     <GIC_SPI 301 IRQ_TYPE_LEVEL_HIGH 0>,
				     <GIC_SPI 778 IRQ_TYPE_LEVEL_HIGH 0>,
				     <GIC_SPI 779 IRQ_TYPE_LEVEL_HIGH 0>,
				     <GIC_SPI 780 IRQ_TYPE_LEVEL_HIGH 0>,
				     <GIC_SPI 781 IRQ_TYPE_LEVEL_HIGH 0>,
				     <GIC_SPI 782 IRQ_TYPE_LEVEL_HIGH 0>,
				     <GIC_SPI 783 IRQ_TYPE_LEVEL_HIGH 0>,
				     <GIC_SPI 784 IRQ_TYPE_LEVEL_HIGH 0>,
				     <GIC_SPI 785 IRQ_TYPE_LEVEL_HIGH 0>,
				     <GIC_SPI 786 IRQ_TYPE_LEVEL_HIGH 0>;
			clocks = <&pericfg_ao CLK_PERI_AO_AP_DMA_X32W_BCLK>;
			#dma-cells = <1>;
			dma-requests = <12>;
		};

		ssusb0: usb@16701000 {
			compatible = "mediatek,mt8196-mtu3", "mediatek,mtu3";
			reg = <0 0x16701000 0 0x2dff>, <0 0x16703e00 0 0x0100>;
			reg-names = "mac", "ippc";
			ranges = <0 0 0 0x16700000 0 0x3f00>;
			#address-cells = <2>;
			#size-cells = <2>;
			interrupts = <GIC_SPI 599 IRQ_TYPE_LEVEL_HIGH 0>;
			clocks = <&vlpckgen CLK_VLP_USB_TOP>,
				 <&clk26m>,
				 <&clk26m>,
				 <&clk26m>,
				 <&vlpckgen CLK_VLP_USB_XHCI>,
				 <&topckgen CLK_TOP_USB_FMCNT_P1>;
			clock-names = "sys_ck", "ref_ck", "mcu_ck",
				      "dma_ck", "xhci_ck", "frmcnt_ck";
			phys = <&u2port0 PHY_TYPE_USB2>, <&u3port0 PHY_TYPE_USB3>;
			power-domains = <&spm MT8196_POWER_DOMAIN_SSUSB_P0>;
			status = "disabled";

			xhci0: usb@0 {
				compatible = "mediatek,mt8196-xhci", "mediatek,mtk-xhci";
				reg = <0 0 0 0x400>;
				reg-names = "mac";
				interrupts = <GIC_SPI 600 IRQ_TYPE_LEVEL_HIGH 0>;
				clocks = <&vlpckgen CLK_VLP_USB_TOP>;
				clock-names = "sys_ck";
			};
		};

		ssusb1: usb@16711000 {
			compatible = "mediatek,mt8196-mtu3", "mediatek,mtu3";
			reg = <0 0x16711000 0 0x2dff>, <0 0x16713e00 0 0x0100>;
			reg-names = "mac", "ippc";
			ranges = <0 0 0 0x16710000 0 0x3f00>;
			#address-cells = <2>;
			#size-cells = <2>;
			interrupts = <GIC_SPI 602 IRQ_TYPE_LEVEL_HIGH 0>;
			clocks = <&topckgen CLK_TOP_USB_TOP_1P>,
				 <&clk26m>,
				 <&clk26m>,
				 <&clk26m>,
				 <&topckgen CLK_TOP_USB_XHCI_1P>,
				 <&topckgen CLK_TOP_USB_FMCNT_P1>;
			clock-names = "sys_ck", "ref_ck", "mcu_ck",
				      "dma_ck", "xhci_ck", "frmcnt_ck";
			phys = <&u2port1 PHY_TYPE_USB2>;
			power-domains = <&spm MT8196_POWER_DOMAIN_SSUSB_P1>;
			status = "disabled";

			xhci1: usb@0 {
				compatible = "mediatek,mt8196-xhci", "mediatek,mtk-xhci";
				reg = <0 0 0 0x400>;
				reg-names = "mac";
				interrupts = <GIC_SPI 603 IRQ_TYPE_LEVEL_HIGH 0>;
				clocks = <&topckgen CLK_TOP_USB_TOP_1P>;
				clock-names = "sys_ck";
			};
		};

		ssusb2: usb@16721000 {
			compatible = "mediatek,mt8196-mtu3", "mediatek,mtu3";
			reg = <0 0x16721000 0 0x2dff>, <0 0x16723e00 0 0x0100>;
			reg-names = "mac", "ippc";
			ranges = <0 0 0 0x16720000 0 0x3f00>;
			#address-cells = <2>;
			#size-cells = <2>;
			interrupts = <GIC_SPI 670 IRQ_TYPE_LEVEL_HIGH 0>;
			clocks = <&topckgen CLK_TOP_USB_TOP_1P>,
				 <&clk26m>,
				 <&clk26m>,
				 <&clk26m>,
				 <&topckgen CLK_TOP_USB_XHCI_1P>,
				 <&topckgen CLK_TOP_USB_FMCNT_P1>;
			clock-names = "sys_ck", "ref_ck", "mcu_ck",
				      "dma_ck", "xhci_ck", "frmcnt_ck";
			phys = <&u2port2 PHY_TYPE_USB2>, <&u3port1 PHY_TYPE_USB3>;
			power-domains = <&spm MT8196_POWER_DOMAIN_SSUSB_P23>;
			status = "disabled";

			xhci2: usb@0 {
				compatible = "mediatek,mt8196-xhci", "mediatek,mtk-xhci";
				reg = <0 0 0 0x400>;
				reg-names = "mac";
				interrupts = <GIC_SPI 671 IRQ_TYPE_LEVEL_HIGH 0>;
				clocks = <&topckgen CLK_TOP_USB_TOP_1P>;
				clock-names = "sys_ck";
			};
		};

		u2phy0: phy@16730000 {
			compatible = "mediatek,mt8196-xsphy", "mediatek,xsphy";
			ranges = <0x0 0x0 0x16730000 0x700>;
			#address-cells = <1>;
			#size-cells = <1>;
			status = "disabled";

			u2port0: usb-phy@0 {
				reg = <0x0 0x400>;
				clocks = <&clk26m>;
				clock-names = "ref";
				#phy-cells = <1>;
			};
		};

		u2phy1: phy@16740000 {
			compatible = "mediatek,mt8196-xsphy", "mediatek,xsphy";
			ranges = <0x0 0x0 0x16740000 0x700>;
			#address-cells = <1>;
			#size-cells = <1>;
			status = "disabled";

			u2port1: usb-phy@0 {
				reg = <0x0 0x400>;
				clocks = <&clk26m>;
				clock-names = "ref";
				#phy-cells = <1>;
			};
		};

		u2phy2: phy@16750000 {
			compatible = "mediatek,mt8196-xsphy", "mediatek,xsphy";
			ranges = <0x0 0x0 0x16750000 0x10400>;
			#address-cells = <1>;
			#size-cells = <1>;
			power-domains = <&spm MT8196_POWER_DOMAIN_SSUSB_PHY_P2>;
			status = "disabled";

			u2port2: usb-phy@0 {
				reg = <0x0 0x400>;
				clocks = <&clk26m>;
				clock-names = "ref";
				#phy-cells = <1>;
			};

			u3port1: usb-phy@10000 {
				reg = <0x10000 0x400>;
				clocks = <&clk26m>;
				clock-names = "ref";
				#phy-cells = <1>;
			};
		};

		u3phy0: phy@16773000 {
			compatible = "mediatek,mt8196-xsphy", "mediatek,xsphy";
			ranges = <0x0 0x0 0x16773000 0x900>;
			#address-cells = <1>;
			#size-cells = <1>;
			power-domains = <&spm MT8196_POWER_DOMAIN_SSUSB_DP_PHY_P0>;
			status = "disabled";

			u3port0: usb-phy@400 {
				reg = <0x400 0x500>;
				clocks = <&clk26m>;
				clock-names = "ref";
				#phy-cells = <1>;
			};
		};

		ufsphy: ufs-phy@16800000 {
			compatible = "mediatek,mt8196-ufsphy", "mediatek,mt8183-ufsphy";
			reg = <0 0x16800000 0 0x10000>;
			clocks = <&ufs_ao_clk CLK_UFSAO_UNIPRO_SYS>,
				 <&ufs_ao_clk CLK_UFSAO_PHY_SAP>;
			clock-names = "unipro", "mp";
			resets = <&ufs_ao_clk MT8196_UFSAO_RST0_UFS_MPHY>;
			#phy-cells = <0>;
			status = "disabled";
		};

		ufshci: ufshci@16810000 {
			compatible = "mediatek,mt8196-ufshci";
			reg = <0 0x16810000 0 0x2a00>;

			interrupts = <GIC_SPI 320 IRQ_TYPE_LEVEL_HIGH 0>;
			clocks = <&ufs_ao_clk CLK_UFSAO_UFSHCI_UFS>,
				 <&ufs_ao_clk CLK_UFSAO_UFSHCI_AES>,
				 <&clk26m>,
				 <&ufs_ao_clk CLK_UFSAO_UNIPRO_SYS>,
				 <&clk26m>,
				 <&ufs_ao_clk CLK_UFSAO_UNIPRO_SAP>,
				 <&ufs_ao_clk CLK_UFSAO_UNIPRO_TX_SYM>,
				 <&topckgen CLK_TOP_PEXPT0_MEM_SUB>,
				 <&topckgen CLK_TOP_AES_UFSFDE>,
				 <&topckgen CLK_TOP_UNIVPLL_D6>,
				 <&topckgen CLK_TOP_MAINPLL_D4>,
				 <&ufs_ao_clk CLK_UFSAO_UNIPRO_RX_SYM0>,
				 <&ufs_ao_clk CLK_UFSAO_UNIPRO_RX_SYM1>,
				 <&topckgen CLK_TOP_UFS>,
				 <&topckgen CLK_TOP_MAINPLL_D4_D2>,
				 <&topckgen CLK_TOP_UNIVPLL_D5>;
			clock-names = "ufs",
				      "ufs_aes",
				      "ufs_tick",
				      "unipro_sysclk",
				      "unipro_tick",
				      "unipro_mp_bclk",
				      "ufs_tx_symbol",
				      "ufs_mem_sub",
				      "crypt_mux",
				      "crypt_lp",
				      "crypt_perf",
				      "ufs_rx_symbol0",
				      "ufs_rx_symbol1",
				      "ufs_sel",
				      "ufs_sel_min_src",
				      "ufs_sel_max_src";

			phys = <&ufsphy>;

			operating-points-v2 = <&ufs_opp_table>;

			resets = <&ufs_ao_clk MT8196_UFSAO_RST1_UFS_UNIPRO>,
				 <&ufs_ao_clk MT8196_UFSAO_RST1_UFS_CRYPTO>,
				 <&ufs_ao_clk MT8196_UFSAO_RST1_UFSHCI>;
			reset-names = "unipro",
				      "crypto",
				      "hci";
			mediatek,ufs-disable-mcq;
			status = "disabled";
		};

		ufs_ao_clk: clock-controller@168a0000 {
			compatible = "mediatek,mt8196-ufscfg-ao", "syscon";
			reg = <0 0x168a0000 0 0x1000>;
			#clock-cells = <1>;
			#reset-cells = <1>;
		};

		pciephy0: phy@16900000 {
			compatible = "mediatek,mt8196-pcie-sphy";
			reg = <0 0x16900000 0 0x10000>, <0 0x16920000 0 0x10000>;
			reg-names = "sif", "ckm";
			power-domains = <&spm MT8196_POWER_DOMAIN_PEXTP_PHY0>;
			#phy-cells = <0>;
			status = "disabled";
		};

		pcie0: pcie@16910000 {
			compatible = "mediatek,mt8196-pcie";
			device_type = "pci";
			reg = <0 0x16910000 0 0x4000>;
			reg-names = "pcie-mac";
			interrupts = <GIC_SPI 337 IRQ_TYPE_LEVEL_HIGH 0>;
			#address-cells = <3>;
			#size-cells = <2>;
			#interrupt-cells = <1>;
			bus-range = <0x00 0xff>;
			ranges = <0x82000000 0 0x50000000 0x0 0x50000000 0 0x8000000>;

			clocks = <&pextp0cfg_ao CLK_PEXT_PEXTP_MAC_P0_PL_P>,
				 <&pextp0cfg_ao CLK_PEXT_PEXTP_MAC_P0_TL>,
				 <&pextp0cfg_ao CLK_PEXT_PEXTP_MAC_P0_AHB_APB>,
				 <&pextp0cfg_ao CLK_PEXT_PEXTP_VLP_AO_P0_LP>,
				 <&pextp0cfg_ao CLK_PEXT_PEXTP_MAC_P0_REF>,
				 <&pextp0cfg_ao CLK_PEXT_PEXTP_MAC_P0_AXI_250>;
			clock-names = "pl_250m", "tl_26m", "bus", "low_power",
				      "peri_26m", "peri_mem";
			assigned-clocks = <&topckgen CLK_TOP_TL>;
			assigned-clock-parents = <&topckgen CLK_TOP_MAINPLL_D4_D4>;

			phys = <&pciephy0>;
			phy-names = "pcie-phy";

			power-domains = <&spm MT8196_POWER_DOMAIN_PEXTP_MAC0>;
			resets = <&pextp0cfg_ao MT8196_PEXTP0_RST0_PCIE0_PHY>,
				 <&pextp0cfg_ao MT8196_PEXTP0_RST0_PCIE0_MAC>;
			reset-names = "phy", "mac";

			interrupt-map-mask = <0 0 0 7>;
			interrupt-map = <0 0 0 1 &pcie0_intc 0>,
					<0 0 0 2 &pcie0_intc 1>,
					<0 0 0 3 &pcie0_intc 2>,
					<0 0 0 4 &pcie0_intc 3>;
			status = "disabled";

			pcie0_intc: interrupt-controller {
				interrupt-controller;
				#address-cells = <0>;
				#interrupt-cells = <1>;
			};
		};

		pciephy1: phy@16930000 {
			compatible = "mediatek,mt8196-pcie-sphy";
			reg = <0 0x16930000 0 0x10000>, <0 0x16950000 0 0x10000>;
			reg-names = "sif", "ckm";
			power-domains = <&spm MT8196_POWER_DOMAIN_PEXTP_PHY1>;
			num-lanes = <2>;
			#phy-cells = <0>;
			status = "disabled";
		};

		pcie1: pcie@16940000 {
			compatible = "mediatek,mt8196-pcie";
			device_type = "pci";
			reg = <0 0x16940000 0 0x4000>;
			reg-names = "pcie-mac";
			interrupts = <GIC_SPI 338 IRQ_TYPE_LEVEL_HIGH 0>;
			#address-cells = <3>;
			#size-cells = <2>;
			#interrupt-cells = <1>;
			bus-range = <0x00 0xff>;
			ranges = <0x82000000 0 0x58000000 0x0 0x58000000 0 0x18000000>;

			clocks = <&pextp1cfg_ao CLK_PEXT1_PEXTP_MAC_P1_PL_P>,
				 <&pextp1cfg_ao CLK_PEXT1_PEXTP_MAC_P1_TL>,
				 <&pextp1cfg_ao CLK_PEXT1_PEXTP_MAC_P1_AHB_APB>,
				 <&pextp1cfg_ao CLK_PEXT1_PEXTP_VLP_AO_P1_LP>,
				 <&pextp1cfg_ao CLK_PEXT1_PEXTP_MAC_P1_REF>,
				 <&pextp1cfg_ao CLK_PEXT1_PEXTP_MAC_P1_AXI_250>;
			clock-names = "pl_250m", "tl_26m", "bus", "low_power",
				      "peri_26m", "peri_mem";
			assigned-clocks = <&topckgen CLK_TOP_TL_P1>;
			assigned-clock-parents = <&topckgen CLK_TOP_MAINPLL_D4_D4>;

			phys = <&pciephy1>;
			phy-names = "pcie-phy";

			power-domains = <&spm MT8196_POWER_DOMAIN_PEXTP_MAC1>;
			resets = <&pextp1cfg_ao MT8196_PEXTP1_RST0_PCIE1_PHY>,
				 <&pextp1cfg_ao MT8196_PEXTP1_RST0_PCIE1_MAC>;
			reset-names = "phy", "mac";

			interrupt-map-mask = <0 0 0 7>;
			interrupt-map = <0 0 0 1 &pcie1_intc 0>,
					<0 0 0 2 &pcie1_intc 1>,
					<0 0 0 3 &pcie1_intc 2>,
					<0 0 0 4 &pcie1_intc 3>;
			status = "disabled";

			pcie1_intc: interrupt-controller {
				interrupt-controller;
				#address-cells = <0>;
				#interrupt-cells = <1>;
			};
		};

		pciephy2: phy@16960000 {
			compatible = "mediatek,mt8196-pcie-sphy";
			reg = <0 0x16960000 0 0x10000>, <0 0x16980000 0 0x10000>;
			reg-names = "sif", "ckm";
			power-domains = <&spm MT8196_POWER_DOMAIN_PEXTP_PHY2>;
			#phy-cells = <0>;
			status = "disabled";
		};

		pcie2: pcie@16970000 {
			compatible = "mediatek,mt8196-pcie";
			device_type = "pci";
			reg = <0 0x16970000 0 0x4000>;
			reg-names = "pcie-mac";
			#address-cells = <3>;
			#size-cells = <2>;
			#interrupt-cells = <1>;
			interrupts = <GIC_SPI 339 IRQ_TYPE_LEVEL_HIGH 0>;
			bus-range = <0x00 0xff>;
			ranges = <0x82000000 0 0x70000000 0x0 0x70000000 0 0x8000000>;

			clocks = <&pextp1cfg_ao CLK_PEXT1_PEXTP_MAC_P2_PL_P>,
				 <&pextp1cfg_ao CLK_PEXT1_PEXTP_MAC_P2_TL>,
				 <&pextp1cfg_ao CLK_PEXT1_PEXTP_MAC_P2_AHB_APB>,
				 <&pextp1cfg_ao CLK_PEXT1_PEXTP_VLP_AO_P2_LP>,
				 <&pextp1cfg_ao CLK_PEXT1_PEXTP_MAC_P2_REF>,
				 <&pextp1cfg_ao CLK_PEXT1_PEXTP_MAC_P2_AXI_250>;
			clock-names = "pl_250m", "tl_26m", "bus", "low_power",
				      "peri_26m", "peri_mem";
			assigned-clocks = <&topckgen CLK_TOP_TL_P2>;
			assigned-clock-parents = <&topckgen CLK_TOP_MAINPLL_D4_D4>;

			phys = <&pciephy2>;
			phy-names = "pcie-phy";

			power-domains = <&spm MT8196_POWER_DOMAIN_PEXTP_MAC2>;
			resets = <&pextp1cfg_ao MT8196_PEXTP1_RST0_PCIE2_PHY>,
				 <&pextp1cfg_ao MT8196_PEXTP1_RST0_PCIE2_MAC>;
			reset-names = "phy", "mac";

			interrupt-map-mask = <0 0 0 7>;
			interrupt-map = <0 0 0 1 &pcie2_intc 0>,
					<0 0 0 2 &pcie2_intc 1>,
					<0 0 0 3 &pcie2_intc 2>,
					<0 0 0 4 &pcie2_intc 3>;
			status = "disabled";

			pcie2_intc: interrupt-controller {
				interrupt-controller;
				#address-cells = <0>;
				#interrupt-cells = <1>;
			};
		};

		pextp0cfg_ao: clock-controller@169b0000 {
			compatible = "mediatek,mt8196-pextp0cfg-ao", "syscon";
			reg = <0 0x169b0000 0 0x1000>;
			#clock-cells = <1>;
			#reset-cells = <1>;
		};

		pextp1cfg_ao: clock-controller@169e0000 {
			compatible = "mediatek,mt8196-pextp1cfg-ao", "syscon";
			reg = <0 0x169e0000 0 0x1000>;
			#clock-cells = <1>;
			#reset-cells = <1>;
		};

		afe: mt8196-afe-pcm@1a110000 {
			compatible = "mediatek,mt8196-afe";
			reg = <0 0x1a110000 0 0x9000>;
			interrupts = <GIC_SPI 351 IRQ_TYPE_LEVEL_HIGH 0>;
			clocks = <&vlpckgen CLK_VLP_AUD_INTBUS>,
				 <&vlpckgen CLK_VLP_AUD_ENGEN1>,
				 <&vlpckgen CLK_VLP_AUD_ENGEN2>,
				 <&vlpckgen CLK_VLP_AUDIO_H>,
				 <&vlpckgen CLK_VLP_APLL1>,
				 <&vlpckgen CLK_VLP_APLL2>,
				 <&topckgen CLK_TOP_APLL_I2SIN0>,
				 <&topckgen CLK_TOP_APLL_I2SIN1>,
				 <&topckgen CLK_TOP_APLL_FMI2S>,
				 <&topckgen CLK_TOP_APLL12_DIV_TDMOUT_M>,
				 <&topckgen CLK_TOP_APLL12_DIV_TDMOUT_B>,
				 <&topckgen CLK_TOP_ADSP>;
			clock-names = "top_aud_intbus",
				      "top_aud_eng1",
				      "top_aud_eng2",
				      "top_aud_h",
				      "apll1",
				      "apll2",
				      "apll12_div_i2sin0",
				      "apll12_div_i2sin1",
				      "apll12_div_fmi2s",
				      "apll12_div_tdmout_m",
				      "apll12_div_tdmout_b",
				      "top_adsp";
			power-domains = <&spm MT8196_POWER_DOMAIN_AUDIO>;
			status = "disabled";
		};

		adsp_mailbox0: mailbox@1a350100 {
			compatible = "mediatek,mt8196-adsp-mbox", "mediatek,mt8186-adsp-mbox";
			reg = <0 0x1a350100 0 0x1000>;
			interrupts = <GIC_SPI 709 IRQ_TYPE_LEVEL_HIGH 0>;
			#mbox-cells = <0>;
		};

		adsp_mailbox1: mailbox@1a360100 {
			compatible = "mediatek,mt8196-adsp-mbox","mediatek,mt8186-adsp-mbox";
			reg = <0 0x1a360100 0 0x1000>;
			interrupts = <GIC_SPI 710 IRQ_TYPE_LEVEL_HIGH 0>;
			#mbox-cells = <0>;
		};

		adsp: adsp@1a000000 {
			compatible = "mediatek,mt8196-dsp";
			reg = <0 0x1a000000 0 0x5000>,
			      <0 0x1a210000 0 0x80000>,
			      <0 0x1a345000 0 0x300>,
			      <0 0x1a00f000 0 0x1000>;
			reg-names = "cfg", "sram", "sec", "bus";
			clocks = <&topckgen CLK_TOP_ADSP>,
				 <&clk26m>,
				 <&apmixedsys CLK_APMIXED_ADSPPLL>;
			clock-names = "audiodsp",
				      "sys_clk",
				      "adsppll";
			mboxes = <&adsp_mailbox0>, <&adsp_mailbox1>;
			mbox-names = "rx", "tx";
			power-domains = <&spm MT8196_POWER_DOMAIN_ADSP_TOP_DORMANT>;
			status = "disabled";
		};

		scpsys: system-controller@1c004000 {
			compatible = "mediatek,mt8196-scpsys", "syscon", "simple-mfd";
			reg = <0 0x1c004000 0 0x1000>;

			/* System Power Manager */
			spm: power-controller {
				compatible = "mediatek,mt8196-power-controller";
				#address-cells = <1>;
				#size-cells = <0>;
				#power-domain-cells = <1>;
				access-controllers = <&infra_bus>, <&scp_bus>;

				power-domain@MT8196_POWER_DOMAIN_MD {
					reg = <MT8196_POWER_DOMAIN_MD>;
					#power-domain-cells = <0>;
				};

				power-domain@MT8196_POWER_DOMAIN_CONN {
					reg = <MT8196_POWER_DOMAIN_CONN>;
					#power-domain-cells = <0>;
				};

				power-domain@MT8196_POWER_DOMAIN_PERI_ETHER {
					reg = <MT8196_POWER_DOMAIN_PERI_ETHER>;
					#power-domain-cells = <0>;
					clocks = <&topckgen CLK_TOP_GMAC_125M>;
					clock-names = "bus";
				};

				power-domain@MT8196_POWER_DOMAIN_SSUSB_P0 {
					reg = <MT8196_POWER_DOMAIN_SSUSB_P0>;
					#address-cells = <1>;
					#size-cells = <0>;
					#power-domain-cells = <1>;

					power-domain@MT8196_POWER_DOMAIN_SSUSB_DP_PHY_P0 {
						reg = <MT8196_POWER_DOMAIN_SSUSB_DP_PHY_P0>;
						#power-domain-cells = <0>;
					};
				};

				power-domain@MT8196_POWER_DOMAIN_SSUSB_P1 {
					reg = <MT8196_POWER_DOMAIN_SSUSB_P1>;
					#power-domain-cells = <0>;
				};

				power-domain@MT8196_POWER_DOMAIN_SSUSB_P23 {
					reg = <MT8196_POWER_DOMAIN_SSUSB_P23>;
					#address-cells = <1>;
					#size-cells = <0>;
					#power-domain-cells = <1>;

					power-domain@MT8196_POWER_DOMAIN_SSUSB_PHY_P2 {
						reg = <MT8196_POWER_DOMAIN_SSUSB_PHY_P2>;
						#power-domain-cells = <0>;
					};
				};

				power-domain@MT8196_POWER_DOMAIN_PEXTP_MAC0 {
					reg = <MT8196_POWER_DOMAIN_PEXTP_MAC0>;
					#address-cells = <1>;
					#size-cells = <0>;
					#power-domain-cells = <1>;

					power-domain@MT8196_POWER_DOMAIN_PEXTP_PHY0 {
						reg = <MT8196_POWER_DOMAIN_PEXTP_PHY0>;
						clocks = <&pextp0cfg_ao CLK_PEXT_PEXTP_PHY_P0_MCU_BUS>,
							 <&pextp0cfg_ao CLK_PEXT_PEXTP_PHY_P0_PEXTP_REF>;
						clock-names = "bus", "ref";
						#power-domain-cells = <0>;
					};
				};

				power-domain@MT8196_POWER_DOMAIN_PEXTP_MAC1 {
					reg = <MT8196_POWER_DOMAIN_PEXTP_MAC1>;
					#address-cells = <1>;
					#size-cells = <0>;
					#power-domain-cells = <1>;

					power-domain@MT8196_POWER_DOMAIN_PEXTP_PHY1 {
						reg = <MT8196_POWER_DOMAIN_PEXTP_PHY1>;
						clocks = <&pextp1cfg_ao CLK_PEXT1_PEXTP_PHY_P1_MCU_BUS>,
							 <&pextp1cfg_ao CLK_PEXT1_PEXTP_PHY_P1_PEXTP_REF>;
						clock-names = "bus", "ref";
						#power-domain-cells = <0>;
					};
				};

				power-domain@MT8196_POWER_DOMAIN_PEXTP_MAC2 {
					reg = <MT8196_POWER_DOMAIN_PEXTP_MAC2>;
					#address-cells = <1>;
					#size-cells = <0>;
					#power-domain-cells = <1>;

					power-domain@MT8196_POWER_DOMAIN_PEXTP_PHY2 {
						reg = <MT8196_POWER_DOMAIN_PEXTP_PHY2>;
						clocks = <&pextp1cfg_ao CLK_PEXT1_PEXTP_PHY_P2_MCU_BUS>,
							 <&pextp1cfg_ao CLK_PEXT1_PEXTP_PHY_P2_PEXTP_REF>;
						clock-names = "bus", "ref";
						#power-domain-cells = <0>;
					};
				};

				power-domain@MT8196_POWER_DOMAIN_ADSP_AO {
					reg = <MT8196_POWER_DOMAIN_ADSP_AO>;
					#address-cells = <1>;
					#size-cells = <0>;
					#power-domain-cells = <1>;

					power-domain@MT8196_POWER_DOMAIN_ADSP_INFRA {
						reg = <MT8196_POWER_DOMAIN_ADSP_INFRA>;
						#address-cells = <1>;
						#size-cells = <0>;
						#power-domain-cells = <1>;

						power-domain@MT8196_POWER_DOMAIN_AUDIO {
							reg = <MT8196_POWER_DOMAIN_AUDIO>;
							#power-domain-cells = <0>;
						};

						power-domain@MT8196_POWER_DOMAIN_ADSP_TOP_DORMANT {
							reg = <MT8196_POWER_DOMAIN_ADSP_TOP_DORMANT>;
							#power-domain-cells = <0>;
						};
					};
				};
			};
		};

		scp_bus: bus@1c00d000 {
			compatible = "simple-bus";
			reg = <0 0x1c00d000 0 0x1000>;
			#address-cells = <2>;
			#size-cells = <2>;
			ranges;
			#access-controller-cells = <0>;
		};

		watchdog@1c010000 {
			compatible = "mediatek,mt8196-wdt", "mediatek,mt6589-wdt";
			reg = <0 0x1c010000 0 0x1000>;
			#reset-cells = <1>;
			mediatek,disable-extrst;
		};

		system-controller@1c013000 {
			compatible = "mediatek,mt8196-dvfsrc";
			reg = <0 0x1c013000 0 0x1000>;
			clocks = <&vlpckgen CLK_VLP_DVFSRC>;

			regulators {
				compatible = "mediatek,mt8196-dvfsrc-regulator";

				dvfsrc_vcore: dvfsrc-vcore {
					regulator-name = "dvfsrc-vcore";
					regulator-min-microvolt = <575000>;
					regulator-max-microvolt = <875000>;
					regulator-always-on;
				};
			};

			emi_icc: interconnect {
				compatible = "mediatek,mt8196-emi";
				#interconnect-cells = <1>;
			};
		};

		vlpckgen: clock-controller@1c016000 {
			compatible = "mediatek,mt8196-vlpckgen", "syscon";
			reg = <0 0x1c016000 0 0x1000>;
			mediatek,hardware-voter = <&scp_hwv>;
			#clock-cells = <1>;
		};

		spmi-arbiter@1c018000 {
			compatible = "mediatek,mt8196-spmi";
			ranges = <0 0 0x1c018000 0x4900>;
			#address-cells = <1>;
			#size-cells = <1>;

			spmi1: spmi@0 {
				reg = <0 0x900>, <0x4800 0x100>;
				reg-names = "pmif", "spmimst";
				interrupts-extended = <&pio 292 IRQ_TYPE_LEVEL_HIGH>;
				interrupt-names = "rcs";
				interrupt-controller;
				#address-cells = <2>;
				#size-cells = <0>;
				#interrupt-cells = <3>;
				clocks = <&clk32k>,
					 <&vlpckgen CLK_VLP_SPMI_M_TIA_32K>,
					 <&vlpckgen CLK_VLP_SPMI_M_MST>;
				clock-names = "pmif_sys_ck", "pmif_tmr_ck", "spmimst_clk_mux";
			};

			spmi0: spmi@2000 {
				reg = <0x2000 0x900>, <0x4000 0x100>;
				reg-names = "pmif", "spmimst";
				interrupts-extended = <&pio 291 IRQ_TYPE_LEVEL_HIGH>;
				interrupt-names = "rcs";
				interrupt-controller;
				#address-cells = <2>;
				#size-cells = <0>;
				#interrupt-cells = <3>;
				clocks = <&clk32k>,
					 <&vlpckgen CLK_VLP_SPMI_M_TIA_32K>,
					 <&vlpckgen CLK_VLP_SPMI_M_MST>;
				clock-names = "pmif_sys_ck", "pmif_tmr_ck", "spmimst_clk_mux";
			};
		};

		sram@1c350000 {
			compatible = "mmio-sram";
			reg = <0x0 0x1c350000 0x0 0x80>;
			ranges = <0 0x0 0x1c350000 0x80>;
			#address-cells = <1>;
			#size-cells = <1>;

			scmi_tx_shmem: scmi-sram-section@0 {
				compatible = "arm,scmi-shmem";
				reg = <0x0 0x80>;
			};
		};

		tinysys_mbox_tx: mailbox@1c351000 {
			compatible = "mediatek,mt8196-tinysys-mhu-mbox";
			reg = <0 0x1c351000 0 0x1000>;
			interrupts = <GIC_SPI 417 IRQ_TYPE_LEVEL_HIGH 0>;
			#mbox-cells = <1>;
		};

		sram@1c360000 {
			compatible = "mmio-sram";
			reg = <0x0 0x1c360000 0x0 0x80>;
			ranges = <0 0x0 0x1c360000 0x80>;
			#address-cells = <1>;
			#size-cells = <1>;

			scmi_rx_shmem: scmi-sram-section@0 {
				compatible = "arm,scmi-shmem";
				reg = <0x0 0x80>;
			};
		};

		tinysys_mbox_rx: mailbox@1c361000 {
			compatible = "mediatek,mt8196-tinysys-mhu-mbox";
			reg = <0 0x1c361000 0 0x1000>;
			interrupts = <GIC_SPI 418 IRQ_TYPE_LEVEL_HIGH 0>;
			#mbox-cells = <1>;
		};

		systimer: systimer@1c400000 {
			compatible = "mediatek,mt8196-timer", "mediatek,mt6765-timer";
			reg = <0 0x1c400000 0 0x1000>;
			interrupts = <GIC_SPI 813 IRQ_TYPE_LEVEL_HIGH 0>;
			clocks = <&clk13m>;
		};

		gce0: gce@300c0000 {
			compatible = "mediatek,mt8196-gce";
			reg = <0 0x300c0000 0 0x80000>;
			interrupts = <GIC_SPI 483 IRQ_TYPE_LEVEL_HIGH 0>;
			#mbox-cells = <2>;
			iommus = <&mm_smmu 199>; /* remove me */
			mboxes = <&gce0 15 CMDQ_THR_PRIO_1>;
		};

		gce1: gce@30140000 {
			compatible = "mediatek,mt8196-gce";
			reg = <0 0x30140000 0 0x80000>;
			interrupts = <GIC_SPI 482 IRQ_TYPE_LEVEL_HIGH 0>;
			#mbox-cells = <2>;
			iommus = <&mm_smmu 183>; /* remove me */
		};

		/* High Frame Rate Processor System Controller (HFRPSYS) */
		hfrpsys_hwv: system-controller@31b00000 {
			compatible = "mediatek,mt8196-hfrpsys", "syscon", "simple-mfd";
			reg = <0 0x31b00000 0 0x6000>;

			/* HFRPSYS Power Controller with Hardware Voter */
			hpm_hwv: power-controller {
				compatible = "mediatek,mt8196-hwv-hfrp-power-controller";
				#address-cells = <1>;
				#size-cells = <0>;
				#power-domain-cells = <1>;

				/* Power Domains are at end of soc avoiding too far indentation */
			};

			/* HFRPSYS Power Regulators */
			regulators {
				compatible = "mediatek,mt8196-hwv-vmm-regulator";
				//access-controllers = <&vcp>;
				access-controller-names = "vcp";

				vmm_vdisp: vdisp {
					regulator-name = "vdisp";
					regulator-min-microvolt = <575000>;
					regulator-max-microvolt = <875000>;
				};

				vmm_vhwdec: vhwdec {
					regulator-name = "vdec-vcore";
					regulator-min-microvolt = <575000>;
					regulator-max-microvolt = <900000>;
				};
			};
		};

		system-controller@31b50000 {
			compatible = "mediatek,mt8196-hfrpsys", "syscon", "simple-mfd";
			reg = <0 0x31b50000 0 0x1000>;

			/* HFRPSYS Power Manager */
			hpm: power-controller {
				compatible = "mediatek,mt8196-hfrp-power-controller";
				#address-cells = <1>;
				#size-cells = <0>;
				#power-domain-cells = <1>;

				power-domain@MT8196_POWER_DOMAIN_EDPTX {
					reg = <MT8196_POWER_DOMAIN_EDPTX>;
					clocks = <&topckgen_gp2 CLK_TOP2_DVO>;
					clock-names = "power";
					#power-domain-cells = <0>;
				};

				power-domain@MT8196_POWER_DOMAIN_DPTX {
					reg = <MT8196_POWER_DOMAIN_DPTX>;
					#power-domain-cells = <0>;
				};
			};
		};

		dispsys0: display-controller@32000000 {
			compatible = "mediatek,mt8196-dispsys0";
			reg = <0 0x32000000 0 0x1000>;
			mboxes = <&gce0 0 CMDQ_THR_PRIO_4>, <&gce0 1 CMDQ_THR_PRIO_4>;
			power-domains = <&hpm_hwv MT8196_POWER_DOMAIN_DIS0_DORMANT>;
			mediatek,hardware-voter = <&hfrpsys_hwv>;
			#address-cells = <2>;
			#clock-cells = <1>;
			#size-cells = <2>;
			ranges = <0 0 0 0x32000000 0 0x200000>;

			direct-link@200 {
				compatible = "mediatek,mt8196-disp-direct-link";
				reg = <0 0x200 0 0x100>;
				clocks = <&dispsys0 CLK_MM_CONFIG>;
				power-domains = <&hpm_hwv MT8196_POWER_DOMAIN_DIS0_DORMANT>;
				trigger-sources = <&disp0_mutex 16>, <&disp0_mutex 32>;

				ports {
					#address-cells = <1>;
					#size-cells = <0>;

					port@0 {
						#address-cells = <1>;
						#size-cells = <0>;
						reg = <0>;

						dl_in_async0_0: endpoint@0 {
							reg = <0>;
							clocks = <&dispsys0 CLK_MM_DISP_DLI_ASYNC0>;
							remote-endpoint = <&ovl_dl_out_async0_5>;
						};

						dl_in_async0_1: endpoint@1 {
							reg = <1>;
							clocks = <&dispsys0 CLK_MM_DISP_DLI_ASYNC1>;
							remote-endpoint = <&ovl_dl_out_async0_6>;
						};

						dl_in_async0_8: endpoint@2 {
							reg = <2>;
							clocks = <&dispsys0 CLK_MM_DISP_DLI_ASYNC8>;
							remote-endpoint = <&dl_out_async0_3>;
							mediatek,port-id = <8>;
						};
					};

					port@1 {
						#address-cells = <1>;
						#size-cells = <0>;
						reg = <1>;

						dl_out_async0_1: endpoint@0 {
							reg = <0>;
							clocks = <&dispsys0 CLK_MM_DISP_DLO_ASYNC1>;
							remote-endpoint = <&dl_in_async1_1>;
							mediatek,port-id = <1>;
						};

						dl_out_async0_2: endpoint@1 {
							reg = <1>;
							clocks = <&dispsys0 CLK_MM_DISP_DLO_ASYNC2>;
							remote-endpoint = <&dl_in_relay0_1>;
							mediatek,port-id = <2>;
						};

						dl_out_async0_3: endpoint@2 {
							reg = <2>;
							clocks = <&dispsys0 CLK_MM_DISP_DLO_ASYNC3>;
							remote-endpoint = <&dl_in_async0_8>;
							mediatek,port-id = <3>;
						};
					};

					port@2 {
						#address-cells = <1>;
						#size-cells = <0>;
						reg = <2>;

						dl_in_relay0_0: endpoint@0 {
							reg = <0>;
							remote-endpoint = <&rsz0_in>;
						};

						dl_in_relay0_1: endpoint@1 {
							reg = <1>;
							remote-endpoint = <&dl_out_async0_2>;
						};
					};

					port@3 {
						#address-cells = <1>;
						#size-cells = <0>;
						reg = <3>;

						dl_out_relay0_1: endpoint@0 {
							reg = <0>;
							remote-endpoint = <&dither0_out>;
							mediatek,port-id = <1>;
						};

					};
				};
			};

			disp0_mutex: mutex@20000 {
				compatible = "mediatek,mt8196-disp-mutex";
				reg = <0 0x20000 0 0x1000>;
				clocks = <&dispsys0 CLK_MM_DISP_MUTEX0>;
				#trigger-source-cells = <1>;
				mediatek,gce-events = <CMDQ_EVENT_DISP1_STREAM_DONE_ENG_EVENT(0)>,
						      <CMDQ_EVENT_DISP1_STREAM_DONE_ENG_EVENT(1)>;
			};

			aal0: aal@30000 {
				compatible = "mediatek,mt8196-disp-aal", "mediatek-mt8183-disp-aal";
				reg = <0 0x30000 0 0x1000>;
				interrupts = <GIC_SPI 475 IRQ_TYPE_LEVEL_HIGH 0>;
				clocks = <&dispsys0 CLK_MM_DISP_AAL0>;
				trigger-sources = <&disp0_mutex 0>;
			};

			aal1: aal@40000 {
				compatible = "mediatek,mt8196-disp-aal", "mediatek-mt8183-disp-aal";
				reg = <0 0x40000 0 0x1000>;
				interrupts = <GIC_SPI 474 IRQ_TYPE_LEVEL_HIGH 0>;
				clocks = <&dispsys0 CLK_MM_DISP_AAL1>;
				trigger-sources = <&disp0_mutex 1>;
			};

			ccorr0: ccorr@90000 {
				compatible = "mediatek,mt8196-disp-ccorr", "mediatek,mt8192-disp-ccorr";
				reg = <0 0x90000 0 0x1000>;
				clocks = <&dispsys0 CLK_MM_DISP_CCORR0>;
				power-domains = <&hpm_hwv MT8196_POWER_DOMAIN_DIS0_DORMANT>;
				trigger-sources = <&disp0_mutex 6>;

				ports {
					#address-cells = <1>;
					#size-cells = <0>;

					port@0 {
						reg = <0>;
						ccorr0_in: endpoint {
							remote-endpoint = <&tdshp0_out>;
						};
					};

					port@1 {
						reg = <1>;
						ccorr0_out: endpoint {
							remote-endpoint = <&ccorr1_in>;
						};
					};
				};
			};

			ccorr1: ccorr@a0000 {
				compatible = "mediatek,mt8196-disp-ccorr", "mediatek,mt8192-disp-ccorr";
				reg = <0 0xa0000 0 0x1000>;
				clocks = <&dispsys0 CLK_MM_DISP_CCORR1>;
				power-domains = <&hpm_hwv MT8196_POWER_DOMAIN_DIS0_DORMANT>;
				trigger-sources = <&disp0_mutex 7>;

				ports {
					#address-cells = <1>;
					#size-cells = <0>;

					port@0 {
						reg = <0>;
						ccorr1_in: endpoint {
							remote-endpoint = <&ccorr0_out>;
						};
					};

					port@1 {
						reg = <1>;
						ccorr1_out: endpoint {
							remote-endpoint = <&gamma0_in>;
						};
					};
				};
			};

			ccorr2: ccorr@b0000 {
				compatible = "mediatek,mt8196-disp-ccorr", "mediatek,mt8192-disp-ccorr";
				reg = <0 0xb0000 0 0x1000>;
				clocks = <&dispsys0 CLK_MM_DISP_CCORR2>;
				power-domains = <&hpm_hwv MT8196_POWER_DOMAIN_DIS0_DORMANT>;
				trigger-sources = <&disp0_mutex 8>;
			};

			ccorr3: ccorr@c0000 {
				compatible = "mediatek,mt8196-disp-ccorr", "mediatek,mt8192-disp-ccorr";
				reg = <0 0xc0000 0 0x1000>;
				clocks = <&dispsys0 CLK_MM_DISP_CCORR3>;
				power-domains = <&hpm_hwv MT8196_POWER_DOMAIN_DIS0_DORMANT>;
				trigger-sources = <&disp0_mutex 9>;
			};

			dither0: dither@110000 {
				compatible = "mediatek,mt8196-disp-dither", "mediatek,mt8183-disp-dither";
				reg = <0 0x110000 0 0x1000>;
				interrupts = <GIC_SPI 471 IRQ_TYPE_LEVEL_HIGH 0>;
				clocks = <&dispsys0 CLK_MM_DISP_DITHER0>;
				power-domains = <&hpm_hwv MT8196_POWER_DOMAIN_DIS0_DORMANT>;
				trigger-sources = <&disp0_mutex 14>;

				ports {
					#address-cells = <1>;
					#size-cells = <0>;

					port@0 {
						reg = <0>;
						dither0_in: endpoint {
							remote-endpoint = <&postmask0_out>;
						};
					};

					port@1 {
						reg = <1>;
						dither0_out: endpoint {
							remote-endpoint = <&dl_out_relay0_1>;
						};
					};
				};
			};

			dither1: dither@120000 {
				compatible = "mediatek,mt8196-disp-dither", "mediatek,mt8183-disp-dither";
				reg = <0 0x120000 0 0x1000>;
				interrupts = <GIC_SPI 470 IRQ_TYPE_LEVEL_HIGH 0>;
				clocks = <&dispsys0 CLK_MM_DISP_DITHER1>;
				power-domains = <&hpm_hwv MT8196_POWER_DOMAIN_DIS0_DORMANT>;
				trigger-sources = <&disp0_mutex 15>;
			};

			gamma0: gamma@130000 {
				compatible = "mediatek,mt8196-disp-gamma", "mediatek,mt8195-disp-gamma";
				reg = <0 0x130000 0 0x1000>;
				clocks = <&dispsys0 CLK_MM_DISP_GAMMA0>;
				power-domains = <&hpm_hwv MT8196_POWER_DOMAIN_DIS0_DORMANT>;
				trigger-sources = <&disp0_mutex 41>;

				ports {
					#address-cells = <1>;
					#size-cells = <0>;

					port@0 {
						reg = <0>;
						gamma0_in: endpoint {
							remote-endpoint = <&ccorr1_out>;
						};
					};

					port@1 {
						reg = <1>;
						gamma0_out: endpoint {
							remote-endpoint = <&postmask0_in>;
						};
					};
				};
			};

			gamma1: gamma@140000 {
				compatible = "mediatek,mt8196-disp-gamma", "mediatek,mt8195-disp-gamma";
				reg = <0 0x140000 0 0x1000>;
				clocks = <&dispsys0 CLK_MM_DISP_GAMMA1>;
				power-domains = <&hpm_hwv MT8196_POWER_DOMAIN_DIS0_DORMANT>;
				trigger-sources = <&disp0_mutex 42>;
			};

			tdshp0: tdshp@1e0000 {
				compatible = "mediatek,mt8196-disp-tdshp";
				reg = <0 0x1e0000 0 0x1000>;
				clocks = <&dispsys0 CLK_MM_DISP_TDSHP0>;
				power-domains = <&hpm_hwv MT8196_POWER_DOMAIN_DIS0_DORMANT>;
				trigger-sources = <&disp0_mutex 53>;

				ports {
					#address-cells = <1>;
					#size-cells = <0>;

					port@0 {
						reg = <0>;
						tdshp0_in: endpoint {
							remote-endpoint = <&rsz0_out>;
						};
					};

					port@1 {
						reg = <1>;
						tdshp0_out: endpoint {
							remote-endpoint = <&ccorr0_in>;
						};
					};
				};
			};

			tdshp1: tdshp@1f0000 {
				compatible = "mediatek,mt8196-disp-tdshp";
				reg = <0 0x1f0000 0 0x1000>;
				clocks = <&dispsys0 CLK_MM_DISP_TDSHP1>;
				power-domains = <&hpm_hwv MT8196_POWER_DOMAIN_DIS0_DORMANT>;
				trigger-sources = <&disp0_mutex 54>;
			};

			postmask0: postmask@180000 {
				compatible = "mediatek,mt8196-disp-postmask",
					     "mediatek,mt8192-disp-postmask";
				reg = <0 0x180000 0 0x1000>;
				clocks = <&dispsys0 CLK_MM_DISP_POSTMASK0>;
				power-domains = <&hpm_hwv MT8196_POWER_DOMAIN_DIS0_DORMANT>;

				ports {
					#address-cells = <1>;
					#size-cells = <0>;

					port@0 {
						reg = <0>;
						postmask0_in: endpoint {
							remote-endpoint = <&gamma0_out>;
						};
					};

					port@1 {
						reg = <1>;
						postmask0_out: endpoint {
							remote-endpoint = <&dither0_in>;
						};
					};
				};
			};

			postmask1: postmask@190000 {
				compatible = "mediatek,mt8196-disp-postmask",
					     "mediatek,mt8192-disp-postmask";
				reg = <0 0x190000 0 0x1000>;
				clocks = <&dispsys0 CLK_MM_DISP_POSTMASK1>;
				power-domains = <&hpm_hwv MT8196_POWER_DOMAIN_DIS0_DORMANT>;
			};

			mdp_rsz0: resizer@1a0000 {
				compatible = "mediatek,mt8196-disp-rsz";
				reg = <0 0x1a0000 0 0x1000>;
				clocks = <&dispsys0 CLK_MM_MDP_RSZ0>;
				trigger-sources = <&disp0_mutex 50>;
				power-domains = <&hpm_hwv MT8196_POWER_DOMAIN_DIS0_DORMANT>;

				ports {
					#address-cells = <1>;
					#size-cells = <0>;

					port@0 {
						reg = <0>;
						rsz0_in: endpoint {
							remote-endpoint = <&dl_in_relay0_0>;
						};
					};

					port@1 {
						reg = <1>;
						rsz0_out: endpoint {
							remote-endpoint = <&tdshp0_in>;
						};
					};
				};
			};

			mdp_rsz1: resizer@1b0000 {
				compatible = "mediatek,mt8196-disp-rsz";
				reg = <0 0x1b0000 0 0x1000>;
				clocks = <&dispsys0 CLK_MM_MDP_RSZ1>;
				power-domains = <&hpm_hwv MT8196_POWER_DOMAIN_DIS0_DORMANT>;
				trigger-sources = <&disp0_mutex 51>;
			};
		};

		dispsys1: display-controller@32400000 {
			compatible = "mediatek,mt8196-dispsys1";
			reg = <0 0x32400000 0 0x1000>;
			ranges = <0 0 0 0x32400000 0 0x200000>;
			#address-cells = <2>;
			#clock-cells = <1>;
			#size-cells = <2>;
			mboxes = <&gce0 0 CMDQ_THR_PRIO_4>, <&gce0 1 CMDQ_THR_PRIO_4>;
			power-domains = <&hpm_hwv MT8196_POWER_DOMAIN_DIS1_DORMANT>;
			mediatek,hardware-voter = <&hfrpsys_hwv>;

			direct-link@200 {
				compatible = "mediatek,mt8196-disp-direct-link";
				reg = <0 0x200 0 0x100>;
				clocks = <&dispsys1 CLK_MM1_DISPSYS1_CONFIG>;
				trigger-sources = <&disp1_mutex 0>, <&disp1_mutex 0>;

				ports {
					#address-cells = <1>;
					#size-cells = <0>;

					port@0 {
						#address-cells = <1>;
						#size-cells = <0>;
						reg = <0>;

						dl_in_async1_1: endpoint@0 {
							reg = <0>;
							clocks = <&dispsys1 CLK_MM1_DISP_DLI_ASYNC21>;
							remote-endpoint = <&dl_out_async0_1>;
							mediatek,port-id = <1>;
						};
/*
						dl_in_async1_2: endpoint@1 {
							reg = <1>;
							clocks = <&dispsys1 CLK_MM1_DISP_DLI_ASYNC22>;
							//remote-endpoint = <&dsc0_in>;
							mediatek,port-id = <2>;
						};
*/
						dl_in_async1_3: endpoint@2 {
							reg = <2>;
							clocks = <&dispsys1 CLK_MM1_DISP_DLI_ASYNC23>;
							remote-endpoint = <&ovl_dl_out_async1_5>;
							mediatek,port-id = <3>;
						};
					};

					port@1 {
						#address-cells = <1>;
						#size-cells = <0>;
						reg = <1>;

						dl_out_async1_0: endpoint@0 {
							reg = <0>;
							clocks = <&dispsys1 CLK_MM1_DISPSYS1_CONFIG>;
							mediatek,port-id = <1>;
						};
/*
						dl_out_async1_1: endpoint@1 {
							reg = <1>;
							clocks = <&dispsys1 CLK_MM1_DISPSYS1_CONFIG>;
							mediatek,port-id = <1>;
						};
*/
					};

					port@2 {
						#address-cells = <1>;
						#size-cells = <0>;
						reg = <2>;

						dl_in_relay1_1: endpoint@0 {
							reg = <0>;
							remote-endpoint = <&dvo0_in>;
							mediatek,port-id = <1>;
						};
/*
						dl_in_relay1_2: endpoint@1 {
							reg = <1>;
							//remote-endpoint = <&dsc0_in>;
							mediatek,port-id = <2>;
						};
*/
						dl_in_relay1_3: endpoint@2 {
							reg = <2>;
							remote-endpoint = <&dsc1_in>;
							mediatek,port-id = <3>;
						};
					};

					port@3 {
						#address-cells = <1>;
						#size-cells = <0>;
						reg = <3>;

						dl_out_relay1_1: endpoint@0 {
							reg = <0>;
						};
/*
						dl_out_relay1_2: endpoint@1 {
							reg = <1>;
						};
*/
					};
				};
			};

			disp1_mutex: mutex@20000 {
				compatible = "mediatek,mt8196-disp-mutex";
				reg = <0 0x20000 0 0x1000>;
				clocks = <&dispsys1 CLK_MM1_DISP_MUTEX0>;
				#trigger-source-cells = <1>;
			};

			dp_intf0: displayport-interface@30000 {
				compatible = "mediatek,mt8196-dp-intf";
				reg = <0 0x30000 0 0x1000>;
				interrupts = <GIC_SPI 460 IRQ_TYPE_LEVEL_HIGH 0>;
				clocks = <&topckgen_gp2 CLK_TOP2_DP0>,
					 <&dispsys1 CLK_MM1_DISP_DP_INTF0>,
					 <&apmixedsys_gp2 CLK_APMIXED2_TVDPLL1>;
				clock-names = "pixel", "engine", "pll";
				power-domains = <&hpm MT8196_POWER_DOMAIN_DPTX>;
				trigger-sources = <&disp1_mutex 13>;
				status = "fail";
			};

			dp_intf1: displayport-interface@40000 {
				compatible = "mediatek,mt8196-dp-intf";
				reg = <0 0x40000 0 0x1000>;
				interrupts = <GIC_SPI 464 IRQ_TYPE_LEVEL_HIGH 0>;
				clocks = <&topckgen_gp2 CLK_TOP2_DP1>,
					 <&dispsys1 CLK_MM1_DISP_DP_INTF1>,
					 <&apmixedsys_gp2 CLK_APMIXED2_TVDPLL2>;
				clock-names = "pixel", "engine", "pll";
				power-domains = <&hpm MT8196_POWER_DOMAIN_EDPTX>;
				trigger-sources = <&disp1_mutex 14>;
				status = "fail";
			};

			dsc0: dsc@50000 {
				compatible = "mediatek,mt8196-disp-dsc", "mediatek,mt8195-disp-dsc";
				reg = <0 0x50000 0 0x1000>;
				clocks = <&dispsys1 CLK_MM1_DISP_DSC_WRAP0>;
				trigger-sources = <&disp1_mutex 15>;

				ports {
					#address-cells = <1>;
					#size-cells = <0>;

					port@0 {
						#address-cells = <1>;
						#size-cells = <0>;
						reg = <0>;

						dsc0_in: endpoint@1 { reg = <1>; };
					};

					port@1 {
						#address-cells = <1>;
						#size-cells = <0>;
						reg = <1>;

						dsc0_out: endpoint@1 { reg = <1>; };
					};
				};
			};

			dsc1: dsc@60000 {
				compatible = "mediatek,mt8196-disp-dsc", "mediatek,mt8195-disp-dsc";
				reg = <0 0x60000 0 0x1000>;
				clocks = <&dispsys1 CLK_MM1_DISP_DSC_WRAP1>;
				trigger-sources = <&disp1_mutex 17>;

				ports {
					#address-cells = <1>;
					#size-cells = <0>;

					port@0 {
						#address-cells = <1>;
						#size-cells = <0>;
						reg = <0>;

						dsc1_in: endpoint@2 {
							reg = <2>;
							remote-endpoint = <&dl_in_relay1_3>;
						};
					};

					port@1 {
						#address-cells = <1>;
						#size-cells = <0>;
						reg = <1>;

						dsc1_out: endpoint@2 { reg = <2>; };
					};
				};
			};

			dsc2: dsc@70000 {
				compatible = "mediatek,mt8196-disp-dsc", "mediatek,mt8195-disp-dsc";
				reg = <0 0x70000 0 0x1000>;
				clocks = <&dispsys1 CLK_MM1_DISP_DSC_WRAP2>;
				trigger-sources = <&disp1_mutex 19>;
			};

			dsc3: dsc@80000 {
				compatible = "mediatek,mt8196-disp-dsc", "mediatek,mt8195-disp-dsc";
				reg = <0 0x80000 0 0x1000>;
				clocks = <&dispsys1 CLK_MM1_DISP_DSC_WRAP3>;
				trigger-sources = <&disp1_mutex 21>;
			};

			dsi0: dsi@90000 {
				compatible = "mediatek,mt8196-dsi";
				reg = <0 0x90000 0 0x1000>;
				interrupts = <GIC_SPI 453 IRQ_TYPE_LEVEL_HIGH 0>;
				clocks = <&dispsys1 CLK_MM1_DISP_DSI0>,
					 <&dispsys1 CLK_MM1_MOD1>,
					 <&mipi_tx_config0>;
				clock-names = "engine", "digital", "hs";
				power-domains = <&hpm_hwv MT8196_POWER_DOMAIN_DSI_PHY0>;
				phys = <&mipi_tx_config0>;
				phy-names = "dphy";
				trigger-sources = <&disp1_mutex 23>;
				status = "disabled";
			};

			dsi1: dsi@a0000 {
				compatible = "mediatek,mt8196-dsi";
				reg = <0 0x90000 0 0x1000>;
				interrupts = <GIC_SPI 455 IRQ_TYPE_LEVEL_HIGH 0>;
				clocks = <&dispsys1 CLK_MM1_DISP_DSI1>,
					 <&dispsys1 CLK_MM1_MOD2>,
					 <&mipi_tx_config1>;
				clock-names = "engine", "digital", "hs";
				power-domains = <&hpm_hwv MT8196_POWER_DOMAIN_DSI_PHY1>;
				phys = <&mipi_tx_config1>;
				phy-names = "dphy";
				trigger-sources = <&disp1_mutex 25>;
				status = "disabled";
			};

			dsi2: dsi@b0000 {
				compatible = "mediatek,mt8196-dsi";
				reg = <0 0x90000 0 0x1000>;
				interrupts = <GIC_SPI 455 IRQ_TYPE_LEVEL_HIGH 0>;
				clocks = <&dispsys1 CLK_MM1_DISP_DSI2>,
					 <&dispsys1 CLK_MM1_MOD3>,
					 <&mipi_tx_config2>;
				clock-names = "engine", "digital", "hs";
				power-domains = <&hpm_hwv MT8196_POWER_DOMAIN_DSI_PHY2>;
				phys = <&mipi_tx_config2>;
				phy-names = "dphy";
				trigger-sources = <&disp1_mutex 27>;
				status = "disabled";
			};

			dvo0: dvo@c0000 {
				compatible = "mediatek,mt8196-edp-dvo"; /* Digital Video Out */
				reg = <0 0xc0000 0 0x1000>;
				interrupts = <GIC_SPI 461 IRQ_TYPE_LEVEL_HIGH 0>;
				clocks = <&dispsys1 CLK_MM1_DISP_DVO0>,
					 <&dispsys1 CLK_MM1_MOD6>,
					 <&apmixedsys_gp2 CLK_APMIXED2_TVDPLL3>;
				clock-names = "pixel", "engine", "pll";
				power-domains = <&hpm_hwv MT8196_POWER_DOMAIN_DIS0_DORMANT>;
				trigger-sources = <&disp1_mutex 29>;
				status = "disabled";

				ports {
					#address-cells = <1>;
					#size-cells = <0>;

					port@0 {
						#address-cells = <1>;
						#size-cells = <0>;
						reg = <0>;

						dvo0_in: endpoint@0 {
							reg = <0>;
							remote-endpoint = <&dl_in_relay1_1>;
						};
					};

					port@1 {
						#address-cells = <1>;
						#size-cells = <0>;
						reg = <1>;

						dvo0_out: endpoint@0 { reg = <0>; };
					};
				};
			};

			disp1_dither2: dither@130000 {
				compatible = "mediatek,mt8196-disp-dither", "mediatek,mt8183-disp-dither";
				reg = <0 0x130000 0 0x1000>;
				interrupts = <GIC_SPI 469 IRQ_TYPE_LEVEL_HIGH 0>;
				clocks = <&dispsys1 CLK_MM1_DISP_DITHER2>;
				trigger-sources = <&disp1_mutex 36>;
			};
		};

		ovlsys0: display-controller@32800000 {
			compatible = "mediatek,mt8196-ovlsys0";
			reg = <0 0x32800000 0 0x1000>;
			mboxes = <&gce0 0 CMDQ_THR_PRIO_4>, <&gce0 1 CMDQ_THR_PRIO_4>,
				 <&gce0 8 CMDQ_THR_PRIO_4>, <&gce0 9 CMDQ_THR_PRIO_4>;
			power-domains = <&hpm_hwv MT8196_POWER_DOMAIN_OVL0_DORMANT>;
			mediatek,hardware-voter = <&hfrpsys_hwv>;
			#address-cells = <2>;
			#clock-cells = <1>;
			#size-cells = <2>;
			ranges = <0 0 0 0x32800000 0 0x200000>;

			port {
				#address-cells = <1>;
				#size-cells = <0>;

				ovlsys0_ep_main: endpoint@0 {
					reg = <0>;
					remote-endpoint = <&ovl0_resizer0_in>;
				};
/*
				ovlsys0_ep_ext: endpoint@1 {
					reg = <1>;
					remote-endpoint = <&exdma0_6_in>;
				};
*/
			};

			direct-link@260 {
				compatible = "mediatek,mt8196-ovl-direct-link";
				reg = <0 0x260 0 0x100>;
				clocks = <&ovlsys0 CLK_OVLSYS_CONFIG>;
				power-domains = <&hpm_hwv MT8196_POWER_DOMAIN_OVL0_DORMANT>;
				trigger-sources = <&ovl0_mutex 34>, <&ovl0_mutex 43>;

				ports {
					#address-cells = <1>;
					#size-cells = <0>;

					port@0 {
						#address-cells = <1>;
						#size-cells = <0>;
						reg = <0>;

						ovl_dl_in_async0_0: endpoint@0 {
							reg = <0>;
							clocks = <&ovlsys0 CLK_OVL_DLI0>;
							mediatek,port-id = <5>;
						};

						ovl_dl_in_async0_1: endpoint@1 {
							reg = <1>;
							clocks = <&ovlsys0 CLK_OVL_DLI1>;
							mediatek,port-id = <6>;
						};
					};

					port@1 {
						#address-cells = <1>;
						#size-cells = <0>;
						reg = <1>;

						ovl_dl_out_async0_5: endpoint@0 {
							reg = <0>;
							clocks = <&ovlsys0 CLK_OVL_DLO5>;
							remote-endpoint = <&dl_in_async0_0>;
							mediatek,port-id = <5>;
						};

						ovl_dl_out_async0_6: endpoint@1 {
							reg = <1>;
							clocks = <&ovlsys0 CLK_OVL_DLO6>;
							remote-endpoint = <&dl_in_async0_1>;
							mediatek,port-id = <6>;
						};
					};

					port@2 { /* IN relay */
						#address-cells = <1>;
						#size-cells = <0>;
						reg = <2>;
					};

					port@3 {
						#address-cells = <1>;
						#size-cells = <0>;
						reg = <3>;

						ovl_dl_out_relay0_5: endpoint@0 {
							reg = <0>;
							remote-endpoint = <&outproc0_0_out>;
							mediatek,port-id = <5>;
						};

						ovl_dl_out_relay0_6: endpoint@1 {
							reg = <1>;
							remote-endpoint = <&outproc0_1_out>;
							mediatek,port-id = <6>;
						};
					};
				};
			};

			ovl0_mutex: mutex@20000 {
				compatible = "mediatek,mt8196-disp-mutex";
				reg = <0 0x20000 0 0x1000>;
				clocks = <&ovlsys0 CLK_OVL_MUTEX0>;
				#trigger-source-cells = <1>;
				mediatek,gce-events = <CMDQ_EVENT_DISP1_STREAM_DONE_ENG_EVENT(0)>,
						      <CMDQ_EVENT_DISP1_STREAM_DONE_ENG_EVENT(1)>;
			};

			ovl0_exdma2: dma-controller@50000 {
				compatible = "mediatek,mt8196-disp-exdma";
				reg = <0 0x50000 0 0x1000>;
				#dma-cells = <1>;
				clocks = <&ovlsys0 CLK_OVL_EXDMA2>;
				iommus = <&mm_smmu 144>;
				power-domains = <&hpm_hwv MT8196_POWER_DOMAIN_OVL0_DORMANT>;
				mediatek,larb = <&smi_larb0>;
				trigger-sources = <&ovl0_mutex 2>;

				ports {
					#address-cells = <1>;
					#size-cells = <0>;

					port@0 {
						reg = <0>;
						exdma0_2_in: endpoint {
							remote-endpoint = <&ovl0_resizer0_out>;
						};
					};

					port@1 {
						reg = <1>;
						exdma0_2_out: endpoint {
							remote-endpoint = <&blender0_1_in>;
						};
					};
				};
			};

			ovl0_exdma3: dma-controller@60000 {
				compatible = "mediatek,mt8196-disp-exdma";
				reg = <0 0x60000 0 0x1000>;
				#dma-cells = <1>;
				clocks = <&ovlsys0 CLK_OVL_EXDMA3>;
				power-domains = <&hpm_hwv MT8196_POWER_DOMAIN_OVL0_DORMANT>;
				trigger-sources = <&ovl0_mutex 3>;
				mediatek,larb = <&smi_larb1>;

				ports {
					#address-cells = <1>;
					#size-cells = <0>;

					port@0 {
						reg = <0>;
						exdma0_3_in: endpoint {
							remote-endpoint = <&blender0_1_out>;
						};
					};

					port@1 {
						reg = <1>;
						exdma0_3_out: endpoint {
							remote-endpoint = <&blender0_2_in>;
						};
					};
				};
			};

			ovl0_exdma4: dma-controller@70000 {
				compatible = "mediatek,mt8196-disp-exdma";
				reg = <0 0x70000 0 0x1000>;
				#dma-cells = <1>;
				clocks = <&ovlsys0 CLK_OVL_EXDMA4>;
				power-domains = <&hpm_hwv MT8196_POWER_DOMAIN_OVL0_DORMANT>;
				trigger-sources = <&ovl0_mutex 4>;
				mediatek,larb = <&smi_larb20>;

				ports {
					#address-cells = <1>;
					#size-cells = <0>;

					port@0 {
						reg = <0>;
						exdma0_4_in: endpoint {
							remote-endpoint = <&blender0_2_out>;
						};
					};

					port@1 {
						reg = <1>;
						exdma0_4_out: endpoint {
							remote-endpoint = <&blender0_3_in>;
						};
					};
				};
			};

			ovl0_exdma5: dma-controller@80000 {
				compatible = "mediatek,mt8196-disp-exdma";
				reg = <0 0x80000 0 0x1000>;
				#dma-cells = <1>;
				clocks = <&ovlsys0 CLK_OVL_EXDMA5>;
				power-domains = <&hpm_hwv MT8196_POWER_DOMAIN_OVL0_DORMANT>;
				trigger-sources = <&ovl0_mutex 5>;
				mediatek,larb = <&smi_larb21>;

				ports {
					#address-cells = <1>;
					#size-cells = <0>;

					port@0 {
						reg = <0>;

						exdma0_5_in: endpoint {
							remote-endpoint = <&blender0_3_out>;
						};
					};

					port@1 {
						reg = <1>;
						exdma0_5_out: endpoint {
							remote-endpoint = <&blender0_4_in>;
						};
					};
				};
			};

			ovl0_exdma6: dma-controller@90000 {
				compatible = "mediatek,mt8196-disp-exdma";
				reg = <0 0x90000 0 0x1000>;
				#dma-cells = <1>;
				clocks = <&ovlsys0 CLK_OVL_EXDMA6>;
				power-domains = <&hpm_hwv MT8196_POWER_DOMAIN_OVL0_DORMANT>;
				trigger-sources = <&ovl0_mutex 6>;
				mediatek,larb = <&smi_larb1>;

				ports {
					#address-cells = <1>;
					#size-cells = <0>;

					port@0 {
						#address-cells = <1>;
						#size-cells = <0>;
						reg = <0>;

						exdma0_6_in: endpoint@1 {
							reg = <1>;
							//remote-endpoint = <&ovlsys0_ep_ext>;
						};
					};

					port@1 {
						#address-cells = <1>;
						#size-cells = <0>;
						reg = <1>;

						exdma0_6_out: endpoint@1 {
							reg = <1>;
							remote-endpoint = <&blender0_5_in>;
						};
					};
				};
			};

			ovl0_exdma7: dma-controller@a0000 {
				compatible = "mediatek,mt8196-disp-exdma";
				reg = <0 0xa0000 0 0x1000>;
				#dma-cells = <1>;
				clocks = <&ovlsys0 CLK_OVL_EXDMA7>;
				power-domains = <&hpm_hwv MT8196_POWER_DOMAIN_OVL0_DORMANT>;
				trigger-sources = <&ovl0_mutex 7>;
				mediatek,larb = <&smi_larb0>;

				ports {
					#address-cells = <1>;
					#size-cells = <0>;

					port@0 {
						#address-cells = <1>;
						#size-cells = <0>;
						reg = <0>;

						exdma0_7_in: endpoint@1 {
							reg = <1>;
							remote-endpoint = <&blender0_5_out>;
						};
					};

					port@1 {
						#address-cells = <1>;
						#size-cells = <0>;
						reg = <1>;

						exdma0_7_out: endpoint@1 {
							reg = <1>;
							remote-endpoint = <&blender0_6_in>;
						};
					};
				};
			};

			ovl0_exdma8: dma-controller@b0000 {
				compatible = "mediatek,mt8196-disp-exdma";
				reg = <0 0xb0000 0 0x1000>;
				#dma-cells = <1>;
				clocks = <&ovlsys0 CLK_OVL_EXDMA8>;
				power-domains = <&hpm_hwv MT8196_POWER_DOMAIN_OVL0_DORMANT>;
				trigger-sources = <&ovl0_mutex 8>;
				mediatek,larb = <&smi_larb21>;

				ports {
					#address-cells = <1>;
					#size-cells = <0>;

					port@0 {
						#address-cells = <1>;
						#size-cells = <0>;
						reg = <0>;

						exdma0_8_in: endpoint@1 {
							reg = <1>;
							remote-endpoint = <&blender0_6_out>;
						};
					};

					port@1 {
						#address-cells = <1>;
						#size-cells = <0>;
						reg = <1>;

						exdma0_8_out: endpoint@1 {
							reg = <1>;
							remote-endpoint = <&blender0_7_in>;
						};
					};
				};
			};

			ovl0_exdma9: dma-controller@c0000 {
				compatible = "mediatek,mt8196-disp-exdma";
				reg = <0 0xc0000 0 0x1000>;
				#dma-cells = <1>;
				clocks = <&ovlsys0 CLK_OVL_EXDMA9>;
				power-domains = <&hpm_hwv MT8196_POWER_DOMAIN_OVL0_DORMANT>;
				trigger-sources = <&ovl0_mutex 9>;
				mediatek,larb = <&smi_larb20>;

				ports {
					#address-cells = <1>;
					#size-cells = <0>;

					port@0 {
						#address-cells = <1>;
						#size-cells = <0>;
						reg = <0>;

						exdma0_9_in: endpoint@1 {
							reg = <1>;
							remote-endpoint = <&blender0_7_out>;
						};
					};

					port@1 {
						#address-cells = <1>;
						#size-cells = <0>;
						reg = <1>;

						exdma0_9_out: endpoint@1 {
							reg = <1>;
							remote-endpoint = <&blender0_8_in>;
						};
					};
				};
			};

			ovl0_blender0: blender@d0000 {
				compatible = "mediatek,mt8196-disp-blender";
				reg = <0 0xd0000 0 0x1000>;
				clocks = <&ovlsys0 CLK_OVL_BLENDER0>;
				power-domains = <&hpm_hwv MT8196_POWER_DOMAIN_OVL0_DORMANT>;
				trigger-sources = <&ovl0_mutex 10>;
			};

			ovl0_blender1: blender@e0000 {
				compatible = "mediatek,mt8196-disp-blender";
				reg = <0 0xe0000 0 0x1000>;
				clocks = <&ovlsys0 CLK_OVL_BLENDER1>;
				power-domains = <&hpm_hwv MT8196_POWER_DOMAIN_OVL0_DORMANT>;
				trigger-sources = <&ovl0_mutex 11>;

				ports {
					#address-cells = <1>;
					#size-cells = <0>;

					port@0 {
						reg = <0>;

						blender0_1_in: endpoint {
							remote-endpoint = <&exdma0_2_out>;
						};
					};

					port@1 {
						reg = <1>;

						blender0_1_out: endpoint {
							remote-endpoint = <&exdma0_3_in>;
						};
					};
				};
			};

			ovl0_blender2: blender@f0000 {
				compatible = "mediatek,mt8196-disp-blender";
				reg = <0 0xf0000 0 0x1000>;
				clocks = <&ovlsys0 CLK_OVL_BLENDER2>;
				power-domains = <&hpm_hwv MT8196_POWER_DOMAIN_OVL0_DORMANT>;
				trigger-sources = <&ovl0_mutex 12>;

				ports {
					#address-cells = <1>;
					#size-cells = <0>;

					port@0 {
						reg = <0>;

						blender0_2_in: endpoint {
							remote-endpoint = <&exdma0_3_out>;
						};
					};

					port@1 {
						reg = <1>;

						blender0_2_out: endpoint {
							remote-endpoint = <&exdma0_4_in>;
						};
					};
				};
			};

			ovl0_blender3: blender@100000 {
				compatible = "mediatek,mt8196-disp-blender";
				reg = <0 0x100000 0 0x1000>;
				clocks = <&ovlsys0 CLK_OVL_BLENDER3>;
				power-domains = <&hpm_hwv MT8196_POWER_DOMAIN_OVL0_DORMANT>;
				trigger-sources = <&ovl0_mutex 13>;

				ports {
					#address-cells = <1>;
					#size-cells = <0>;

					port@0 {
						reg = <0>;

						blender0_3_in: endpoint {
							remote-endpoint = <&exdma0_4_out>;
						};
					};

					port@1 {
						reg = <1>;

						blender0_3_out: endpoint {
							remote-endpoint = <&exdma0_5_in>;
						};
					};
				};
			};

			ovl0_blender4: blender@110000 {
				compatible = "mediatek,mt8196-disp-blender";
				reg = <0 0x110000 0 0x1000>;
				clocks = <&ovlsys0 CLK_OVL_BLENDER4>;
				power-domains = <&hpm_hwv MT8196_POWER_DOMAIN_OVL0_DORMANT>;
				trigger-sources = <&ovl0_mutex 14>;

				ports {
					#address-cells = <1>;
					#size-cells = <0>;

					port@0 {
						reg = <0>;

						blender0_4_in: endpoint {
							remote-endpoint = <&exdma0_5_out>;
						};
					};

					port@1 {
						reg = <1>;

						blender0_4_out: endpoint {
							remote-endpoint = <&outproc0_0_in>;
						};
					};
				};
			};

			ovl0_blender5: blender@120000 {
				compatible = "mediatek,mt8196-disp-blender";
				reg = <0 0x120000 0 0x1000>;
				clocks = <&ovlsys0 CLK_OVL_BLENDER5>;
				power-domains = <&hpm_hwv MT8196_POWER_DOMAIN_OVL0_DORMANT>;
				trigger-sources = <&ovl0_mutex 15>;

				ports {
					#address-cells = <1>;
					#size-cells = <0>;

					port@0 {
						#address-cells = <1>;
						#size-cells = <0>;
						reg = <0>;

						blender0_5_in: endpoint@1 {
							reg = <1>;
							remote-endpoint = <&exdma0_6_out>;
						};
					};

					port@1 {
						#address-cells = <1>;
						#size-cells = <0>;
						reg = <1>;

						blender0_5_out: endpoint@1 {
							reg = <1>;
							remote-endpoint = <&exdma0_7_in>;
						};
					};
				};
			};

			ovl0_blender6: blender@130000 {
				compatible = "mediatek,mt8196-disp-blender";
				reg = <0 0x130000 0 0x1000>;
				clocks = <&ovlsys0 CLK_OVL_BLENDER6>;
				power-domains = <&hpm_hwv MT8196_POWER_DOMAIN_OVL0_DORMANT>;
				trigger-sources = <&ovl0_mutex 16>;

				ports {
					#address-cells = <1>;
					#size-cells = <0>;

					port@0 {
						#address-cells = <1>;
						#size-cells = <0>;
						reg = <0>;

						blender0_6_in: endpoint@1 {
							reg = <1>;
							remote-endpoint = <&exdma0_7_out>;
						};
					};

					port@1 {
						#address-cells = <1>;
						#size-cells = <0>;
						reg = <1>;

						blender0_6_out: endpoint@1 {
							reg = <1>;
							remote-endpoint = <&exdma0_8_in>;
						};
					};
				};
			};

			ovl0_blender7: blender@140000 {
				compatible = "mediatek,mt8196-disp-blender";
				reg = <0 0x140000 0 0x1000>;
				clocks = <&ovlsys0 CLK_OVL_BLENDER7>;
				power-domains = <&hpm_hwv MT8196_POWER_DOMAIN_OVL0_DORMANT>;
				trigger-sources = <&ovl0_mutex 17>;

				ports {
					#address-cells = <1>;
					#size-cells = <0>;

					port@0 {
						#address-cells = <1>;
						#size-cells = <0>;
						reg = <0>;

						blender0_7_in: endpoint@1 {
							reg = <1>;
							remote-endpoint = <&exdma0_8_out>;
						};
					};

					port@1 {
						#address-cells = <1>;
						#size-cells = <0>;
						reg = <1>;

						blender0_7_out: endpoint@1 {
							reg = <1>;
							remote-endpoint = <&exdma0_9_in>;
						};
					};
				};
			};

			ovl0_blender8: blender@150000 {
				compatible = "mediatek,mt8196-disp-blender";
				reg = <0 0x150000 0 0x1000>;
				clocks = <&ovlsys0 CLK_OVL_BLENDER8>;
				power-domains = <&hpm_hwv MT8196_POWER_DOMAIN_OVL0_DORMANT>;
				trigger-sources = <&ovl0_mutex 18>;

				ports {
					#address-cells = <1>;
					#size-cells = <0>;

					port@0 {
						#address-cells = <1>;
						#size-cells = <0>;
						reg = <0>;

						blender0_8_in: endpoint@1 {
							reg = <1>;
							remote-endpoint = <&exdma0_9_out>;
						};
					};

					port@1 {
						#address-cells = <1>;
						#size-cells = <0>;
						reg = <1>;

						blender0_8_out: endpoint@1 {
							reg = <1>;
							remote-endpoint = <&outproc0_1_in>;
						};
					};
				};
			};

			ovl0_blender9: blender@160000 {
				compatible = "mediatek,mt8196-disp-blender";
				reg = <0 0x160000 0 0x1000>;
				clocks = <&ovlsys0 CLK_OVL_BLENDER9>;
				power-domains = <&hpm_hwv MT8196_POWER_DOMAIN_OVL0_DORMANT>;
				trigger-sources = <&ovl0_mutex 19>;
			};

			ovl0_outproc0: outproc@170000 {
				compatible = "mediatek,mt8196-disp-outproc";
				reg = <0 0x170000 0 0x1000>;
				clocks = <&ovlsys0 CLK_OVL_OUTPROC0>;
				interrupts = <GIC_SPI 450 IRQ_TYPE_LEVEL_HIGH 0>;
				mboxes = <&gce0 3 CMDQ_THR_PRIO_4>;
				mediatek,gce-events = <CMDQ_EVENT_OVL0_FRAME_DONE_SEL(0)>;
				trigger-sources = <&ovl0_mutex 20>;

				ports {
					#address-cells = <1>;
					#size-cells = <0>;

					port@0 {
						reg = <0>;
						outproc0_0_in: endpoint {
							remote-endpoint = <&blender0_4_out>;
						};
					};

					port@1 {
						reg = <1>;
						outproc0_0_out: endpoint {
							remote-endpoint = <&ovl_dl_out_relay0_5>;
						};
					};
				};
			};

			ovl0_outproc1: outproc@180000 {
				compatible = "mediatek,mt8196-disp-outproc";
				reg = <0 0x180000 0 0x1000>;
				clocks = <&ovlsys0 CLK_OVL_OUTPROC1>;
				interrupts = <GIC_SPI 451 IRQ_TYPE_LEVEL_HIGH 0>;
				trigger-sources = <&ovl0_mutex 21>;

				ports {
					#address-cells = <1>;
					#size-cells = <0>;

					port@0 {
						#address-cells = <1>;
						#size-cells = <0>;
						reg = <0>;

						outproc0_1_in: endpoint@1 {
							reg = <1>;
							remote-endpoint = <&blender0_8_out>;
						};
					};

					port@1 {
						#address-cells = <1>;
						#size-cells = <0>;
						reg = <1>;

						outproc0_1_out: endpoint@1 {
							reg = <1>;
							remote-endpoint = <&ovl_dl_out_relay0_6>;
						};
					};
				};
			};

			ovl0_outproc2: outproc@190000 {
				compatible = "mediatek,mt8196-disp-outproc";
				reg = <0 0x190000 0 0x1000>;
				clocks = <&ovlsys0 CLK_OVL_OUTPROC2>;
				trigger-sources = <&ovl0_mutex 22>;
			};

			ovl0_outproc3: outproc@1a0000 {
				compatible = "mediatek,mt8196-disp-outproc";
				reg = <0 0x1a0000 0 0x1000>;
				clocks = <&ovlsys0 CLK_OVL_OUTPROC3>;
				trigger-sources = <&ovl0_mutex 23>;
			};

			ovl0_outproc4: outproc@1b0000 {
				compatible = "mediatek,mt8196-disp-outproc";
				reg = <0 0x1b0000 0 0x1000>;
				clocks = <&ovlsys0 CLK_OVL_OUTPROC4>;
				trigger-sources = <&ovl0_mutex 24>;
			};

			ovl0_outproc5: outproc@1c0000 {
				compatible = "mediatek,mt8196-disp-outproc";
				reg = <0 0x1c0000 0 0x1000>;
				clocks = <&ovlsys0 CLK_OVL_OUTPROC5>;
				trigger-sources = <&ovl0_mutex 25>;
			};

			ovl0_rsz0: resizer@1d0000 {
				compatible = "mediatek,mt8196-disp-rsz";
				reg = <0 0x1d0000 0 0x1000>;
				clocks = <&ovlsys0 CLK_OVL_MDP_RSZ0>;
				trigger-sources = <&ovl0_mutex 26>;
				power-domains = <&hpm_hwv MT8196_POWER_DOMAIN_OVL0_DORMANT>;

				ports {
					#address-cells = <1>;
					#size-cells = <0>;

					port@0 {
						reg = <0>;
						ovl0_resizer0_in: endpoint {
							remote-endpoint = <&ovlsys0_ep_main>;
						};
					};

					port@1 {
						reg = <1>;
						ovl0_resizer0_out: endpoint {
							remote-endpoint = <&exdma0_2_in>;
						};
					};
				};
			};

			ovl0_rsz1: resizer@1e0000 {
				compatible = "mediatek,mt8196-disp-rsz";
				reg = <0 0x1e0000 0 0x1000>;
				clocks = <&ovlsys0 CLK_OVL_MDP_RSZ1>;
				power-domains = <&hpm_hwv MT8196_POWER_DOMAIN_OVL0_DORMANT>;
				trigger-sources = <&ovl0_mutex 27>;
				status = "disabled";
			};
		};

		ovlsys1: display-controller@32c00000 {
			compatible = "mediatek,mt8196-ovlsys1";
			reg = <0 0x32c00000 0 0x1000>;
			#address-cells = <2>;
			#clock-cells = <1>;
			#dma-cells = <1>;
			#size-cells = <2>;
			mboxes = <&gce0 2 CMDQ_THR_PRIO_4>, <&gce0 10 CMDQ_THR_PRIO_4>;
			power-domains = <&hpm_hwv MT8196_POWER_DOMAIN_OVL1_DORMANT>;
			mediatek,hardware-voter = <&hfrpsys_hwv>;
			ranges = <0 0 0 0x32c00000 0 0x200000>;

			port {
				#address-cells = <1>;
				#size-cells = <0>;

				ovlsys1_ep_third: endpoint@2 {
					reg = <2>;
					remote-endpoint = <&ovl1_resizer0_in>;
				};
			};

			direct-link@260 {
				compatible = "mediatek,mt8196-ovl-direct-link";
				reg = <0 0x260 0 0x100>;
				clocks = <&ovlsys1 CLK_OVL1_OVLSYS_CONFIG>;
				power-domains = <&hpm_hwv MT8196_POWER_DOMAIN_OVL1_DORMANT>;
				trigger-sources = <&ovl1_mutex 34>, <&ovl1_mutex 43>;

				ports {
					#address-cells = <1>;
					#size-cells = <0>;

					port@0 {
						#address-cells = <1>;
						#size-cells = <0>;
						reg = <0>;

						ovl_dl_in_async1_0: endpoint@0 {
							reg = <0>;
							clocks = <&ovlsys1 CLK_OVL1_DLI0>;
						};

						ovl_dl_in_async1_1: endpoint@1 {
							reg = <1>;
							clocks = <&ovlsys1 CLK_OVL1_DLI1>;
						};

						ovl_dl_in_async1_2: endpoint@2 {
							reg = <2>;
							clocks = <&ovlsys1 CLK_OVL1_DLI2>;
						};
					};

					port@1 {
						#address-cells = <1>;
						#size-cells = <0>;
						reg = <1>;

						ovl_dl_out_async1_0: endpoint@0 {
							reg = <0>;
							clocks = <&ovlsys1 CLK_OVL1_DLO0>;
						};

						ovl_dl_out_async1_1: endpoint@1 {
							reg = <1>;
							clocks = <&ovlsys1 CLK_OVL1_DLO1>;
						};

						ovl_dl_out_async1_5: endpoint@2 {
							reg = <2>;
							clocks = <&ovlsys1 CLK_OVL1_DLO5>;
							remote-endpoint = <&dl_in_async1_3>;
							mediatek,port-id = <5>;
						};
					};

					port@2 { /* IN relay */
						#address-cells = <1>;
						#size-cells = <0>;
						reg = <2>;
					};

					port@3 {
						#address-cells = <1>;
						#size-cells = <0>;
						reg = <3>;

						ovl_dl_out_relay1_5: endpoint@2 {
							reg = <2>;
							remote-endpoint = <&outproc1_0_out>;
							mediatek,port-id = <5>;
						};
					};
				};
			};


			ovl1_mutex: mutex@20000 {
				compatible = "mediatek,mt8196-disp-mutex";
				reg = <0 0x20000 0 0x1000>;
				clocks = <&ovlsys1 CLK_OVL1_OVL_MUTEX0>;
				#trigger-source-cells = <1>;
				mediatek,gce-events = <CMDQ_EVENT_DISP1_STREAM_DONE_ENG_EVENT(2)>;
			};

			ovl1_exdma2: dma-controller@50000 {
				compatible = "mediatek,mt8196-disp-exdma";
				reg = <0 0x50000 0 0x1000>;
				#dma-cells = <1>;
				clocks = <&ovlsys1 CLK_OVL1_OVL_EXDMA2>;
				power-domains = <&hpm_hwv MT8196_POWER_DOMAIN_OVL1_DORMANT>;
				trigger-sources = <&ovl1_mutex 2>;
				mediatek,larb = <&smi_larb34>;

				ports {
					#address-cells = <1>;
					#size-cells = <0>;

					port@0 {
						#address-cells = <1>;
						#size-cells = <0>;
						reg = <0>;

						exdma1_2_in: endpoint@2 {
							reg = <2>;
							remote-endpoint = <&ovl1_resizer0_out>;
						};
					};

					port@1 {
						#address-cells = <1>;
						#size-cells = <0>;
						reg = <1>;

						exdma1_2_out: endpoint@2 {
							reg = <2>;
							remote-endpoint = <&blender1_1_in>;
						};
					};
				};
			};

			ovl1_exdma3: dma-controller@60000 {
				compatible = "mediatek,mt8196-disp-exdma";
				reg = <0 0x60000 0 0x1000>;
				#dma-cells = <1>;
				clocks = <&ovlsys1 CLK_OVL1_OVL_EXDMA3>;
				power-domains = <&hpm_hwv MT8196_POWER_DOMAIN_OVL1_DORMANT>;
				trigger-sources = <&ovl1_mutex 3>;
				mediatek,larb = <&smi_larb35>;

				ports {
					#address-cells = <1>;
					#size-cells = <0>;

					port@0 {
						#address-cells = <1>;
						#size-cells = <0>;
						reg = <0>;

						exdma1_3_in: endpoint@2 {
							reg = <2>;
							remote-endpoint = <&blender1_1_out>;
						};
					};

					port@1 {
						#address-cells = <1>;
						#size-cells = <0>;
						reg = <1>;

						exdma1_3_out: endpoint@2 {
							reg = <2>;
							remote-endpoint = <&blender1_2_in>;
						};
					};
				};
			};

			ovl1_exdma4: dma-controller@70000 {
				compatible = "mediatek,mt8196-disp-exdma";
				reg = <0 0x70000 0 0x1000>;
				#dma-cells = <1>;
				clocks = <&ovlsys1 CLK_OVL1_OVL_EXDMA4>;
				power-domains = <&hpm_hwv MT8196_POWER_DOMAIN_OVL1_DORMANT>;
				trigger-sources = <&ovl1_mutex 4>;
				mediatek,larb = <&smi_larb36>;

				ports {
					#address-cells = <1>;
					#size-cells = <0>;

					port@0 {
						#address-cells = <1>;
						#size-cells = <0>;
						reg = <0>;

						exdma1_4_in: endpoint@2 {
							reg = <2>;
							remote-endpoint = <&blender1_2_out>;
						};
					};

					port@1 {
						#address-cells = <1>;
						#size-cells = <0>;
						reg = <1>;

						exdma1_4_out: endpoint@2 {
							reg = <2>;
							remote-endpoint = <&blender1_3_in>;
						};
					};
				};
			};

			ovl1_exdma5: dma-controller@80000 {
				compatible = "mediatek,mt8196-disp-exdma";
				reg = <0 0x80000 0 0x1000>;
				#dma-cells = <1>;
				clocks = <&ovlsys1 CLK_OVL1_OVL_EXDMA5>;
				power-domains = <&hpm_hwv MT8196_POWER_DOMAIN_OVL1_DORMANT>;
				trigger-sources = <&ovl1_mutex 5>;
				mediatek,larb = <&smi_larb37>;

				ports {
					#address-cells = <1>;
					#size-cells = <0>;

					port@0 {
						#address-cells = <1>;
						#size-cells = <0>;
						reg = <0>;

						exdma1_5_in: endpoint@2 {
							reg = <2>;
							remote-endpoint = <&blender1_3_out>;
						};
					};

					port@1 {
						#address-cells = <1>;
						#size-cells = <0>;
						reg = <1>;

						exdma1_5_out: endpoint@2 {
							reg = <2>;
							remote-endpoint = <&blender1_4_in>;
						};
					};
				};
			};

			ovl1_exdma6: dma-controller@90000 {
				compatible = "mediatek,mt8196-disp-exdma";
				reg = <0 0x90000 0 0x1000>;
				#dma-cells = <1>;
				clocks = <&ovlsys1 CLK_OVL1_OVL_EXDMA6>;
				power-domains = <&hpm_hwv MT8196_POWER_DOMAIN_OVL1_DORMANT>;
				trigger-sources = <&ovl1_mutex 6>;
				mediatek,larb = <&smi_larb35>;
			};

			ovl1_exdma7: dma-controller@a0000 {
				compatible = "mediatek,mt8196-disp-exdma";
				reg = <0 0xa0000 0 0x1000>;
				#dma-cells = <1>;
				clocks = <&ovlsys1 CLK_OVL1_OVL_EXDMA7>;
				power-domains = <&hpm_hwv MT8196_POWER_DOMAIN_OVL1_DORMANT>;
				trigger-sources = <&ovl1_mutex 7>;
				mediatek,larb = <&smi_larb34>;
			};

			ovl1_exdma8: dma-controller@b0000 {
				compatible = "mediatek,mt8196-disp-exdma";
				reg = <0 0xb0000 0 0x1000>;
				#dma-cells = <1>;
				clocks = <&ovlsys1 CLK_OVL1_OVL_EXDMA8>;
				power-domains = <&hpm_hwv MT8196_POWER_DOMAIN_OVL1_DORMANT>;
				trigger-sources = <&ovl1_mutex 8>;
				mediatek,larb = <&smi_larb37>;
			};

			ovl1_exdma9: dma-controller@c0000 {
				compatible = "mediatek,mt8196-disp-exdma";
				reg = <0 0xc0000 0 0x1000>;
				#dma-cells = <1>;
				clocks = <&ovlsys1 CLK_OVL1_OVL_EXDMA9>;
				power-domains = <&hpm_hwv MT8196_POWER_DOMAIN_OVL1_DORMANT>;
				trigger-sources = <&ovl1_mutex 9>;
				mediatek,larb = <&smi_larb36>;
			};

			ovl1_blender0: blender@d0000 {
				compatible = "mediatek,mt8196-disp-blender";
				reg = <0 0xd0000 0 0x1000>;
				clocks = <&ovlsys1 CLK_OVL1_OVL_BLENDER0>;
				power-domains = <&hpm_hwv MT8196_POWER_DOMAIN_OVL1_DORMANT>;
				trigger-sources = <&ovl1_mutex 10>;
			};

			ovl1_blender1: blender@e0000 {
				compatible = "mediatek,mt8196-disp-blender";
				reg = <0 0xe0000 0 0x1000>;
				clocks = <&ovlsys1 CLK_OVL1_OVL_BLENDER1>;
				power-domains = <&hpm_hwv MT8196_POWER_DOMAIN_OVL1_DORMANT>;
				trigger-sources = <&ovl1_mutex 11>;

				ports {
					#address-cells = <1>;
					#size-cells = <0>;

					port@0 {
						#address-cells = <1>;
						#size-cells = <0>;
						reg = <0>;

						blender1_1_in: endpoint@2 {
							reg = <2>;
							remote-endpoint = <&exdma1_2_out>;
						};
					};

					port@1 {
						#address-cells = <1>;
						#size-cells = <0>;
						reg = <1>;

						blender1_1_out: endpoint@2 {
							reg = <2>;
							remote-endpoint = <&exdma1_3_in>;
						};
					};
				};
			};

			ovl1_blender2: blender@f0000 {
				compatible = "mediatek,mt8196-disp-blender";
				reg = <0 0xf0000 0 0x1000>;
				clocks = <&ovlsys1 CLK_OVL1_OVL_BLENDER2>;
				power-domains = <&hpm_hwv MT8196_POWER_DOMAIN_OVL1_DORMANT>;
				trigger-sources = <&ovl1_mutex 12>;

				ports {
					#address-cells = <1>;
					#size-cells = <0>;

					port@0 {
						#address-cells = <1>;
						#size-cells = <0>;
						reg = <0>;

						blender1_2_in: endpoint@2 {
							reg = <2>;
							remote-endpoint = <&exdma1_3_out>;
						};
					};

					port@1 {
						#address-cells = <1>;
						#size-cells = <0>;
						reg = <1>;

						blender1_2_out: endpoint@2 {
							reg = <2>;
							remote-endpoint = <&exdma1_4_in>;
						};
					};
				};
			};

			ovl1_blender3: blender@100000 {
				compatible = "mediatek,mt8196-disp-blender";
				reg = <0 0x100000 0 0x1000>;
				clocks = <&ovlsys1 CLK_OVL1_OVL_BLENDER3>;
				power-domains = <&hpm_hwv MT8196_POWER_DOMAIN_OVL1_DORMANT>;
				trigger-sources = <&ovl1_mutex 13>;

				ports {
					#address-cells = <1>;
					#size-cells = <0>;

					port@0 {
						#address-cells = <1>;
						#size-cells = <0>;
						reg = <0>;

						blender1_3_in: endpoint@2 {
							reg = <2>;
							remote-endpoint = <&exdma1_4_out>;
						};
					};

					port@1 {
						#address-cells = <1>;
						#size-cells = <0>;
						reg = <1>;

						blender1_3_out: endpoint@2 {
							reg = <2>;
							remote-endpoint = <&exdma1_5_in>;
						};
					};
				};
			};

			ovl1_blender4: blender@110000 {
				compatible = "mediatek,mt8196-disp-blender";
				reg = <0 0x110000 0 0x1000>;
				clocks = <&ovlsys1 CLK_OVL1_OVL_BLENDER4>;
				power-domains = <&hpm_hwv MT8196_POWER_DOMAIN_OVL1_DORMANT>;
				trigger-sources = <&ovl1_mutex 14>;

				ports {
					#address-cells = <1>;
					#size-cells = <0>;

					port@0 {
						#address-cells = <1>;
						#size-cells = <0>;
						reg = <0>;

						blender1_4_in: endpoint@2 {
							reg = <2>;
							remote-endpoint = <&exdma1_5_out>;
						};
					};

					port@1 {
						#address-cells = <1>;
						#size-cells = <0>;
						reg = <1>;

						blender1_4_out: endpoint@2 {
							reg = <2>;
							remote-endpoint = <&outproc1_0_in>;
						};
					};
				};
			};

			ovl1_blender5: blender@120000 {
				compatible = "mediatek,mt8196-disp-blender";
				reg = <0 0x120000 0 0x1000>;
				clocks = <&ovlsys1 CLK_OVL1_OVL_BLENDER5>;
				power-domains = <&hpm_hwv MT8196_POWER_DOMAIN_OVL1_DORMANT>;
				trigger-sources = <&ovl1_mutex 15>;
			};

			ovl1_blender6: blender@130000 {
				compatible = "mediatek,mt8196-disp-blender";
				reg = <0 0x130000 0 0x1000>;
				clocks = <&ovlsys1 CLK_OVL1_OVL_BLENDER6>;
				power-domains = <&hpm_hwv MT8196_POWER_DOMAIN_OVL1_DORMANT>;
				trigger-sources = <&ovl1_mutex 16>;
			};

			ovl1_blender7: blender@140000 {
				compatible = "mediatek,mt8196-disp-blender";
				reg = <0 0x140000 0 0x1000>;
				clocks = <&ovlsys1 CLK_OVL1_OVL_BLENDER7>;
				power-domains = <&hpm_hwv MT8196_POWER_DOMAIN_OVL1_DORMANT>;
				trigger-sources = <&ovl1_mutex 17>;
			};

			ovl1_blender8: blender@150000 {
				compatible = "mediatek,mt8196-disp-blender";
				reg = <0 0x150000 0 0x1000>;
				clocks = <&ovlsys1 CLK_OVL1_OVL_BLENDER8>;
				power-domains = <&hpm_hwv MT8196_POWER_DOMAIN_OVL1_DORMANT>;
				trigger-sources = <&ovl1_mutex 18>;
			};

			ovl1_blender9: blender@160000 {
				compatible = "mediatek,mt8196-disp-blender";
				reg = <0 0x160000 0 0x1000>;
				clocks = <&ovlsys1 CLK_OVL1_OVL_BLENDER9>;
				power-domains = <&hpm_hwv MT8196_POWER_DOMAIN_OVL1_DORMANT>;
				trigger-sources = <&ovl1_mutex 19>;
			};

			ovl1_outproc0: outproc@170000 {
				compatible = "mediatek,mt8196-disp-outproc";
				reg = <0 0x170000 0 0x1000>;
				clocks = <&ovlsys1 CLK_OVL1_OVL_OUTPROC0>;
				interrupts = <GIC_SPI 452 IRQ_TYPE_LEVEL_HIGH 0>;
				trigger-sources = <&ovl1_mutex 20>;

				ports {
					#address-cells = <1>;
					#size-cells = <0>;

					port@0 {
						#address-cells = <1>;
						#size-cells = <0>;
						reg = <0>;

						outproc1_0_in: endpoint@2 {
							reg = <2>;
							remote-endpoint = <&blender1_4_out>;
						};
					};

					port@1 {
						#address-cells = <1>;
						#size-cells = <0>;
						reg = <1>;

						outproc1_0_out: endpoint@2 {
							reg = <2>;
							remote-endpoint = <&ovl_dl_out_relay1_5>;
						};
					};
				};
			};

			ovl1_outproc1: outproc@180000 {
				compatible = "mediatek,mt8196-disp-outproc";
				reg = <0 0x180000 0 0x1000>;
				clocks = <&ovlsys1 CLK_OVL1_OVL_OUTPROC0>;
				trigger-sources = <&ovl1_mutex 21>;
			};

			ovl1_outproc2: outproc@190000 {
				compatible = "mediatek,mt8196-disp-outproc";
				reg = <0 0x190000 0 0x1000>;
				clocks = <&ovlsys1 CLK_OVL1_OVL_OUTPROC2>;
				trigger-sources = <&ovl1_mutex 22>;
			};

			ovl1_outproc3: outproc@1a0000 {
				compatible = "mediatek,mt8196-disp-outproc";
				reg = <0 0x1a0000 0 0x1000>;
				clocks = <&ovlsys1 CLK_OVL1_OVL_OUTPROC3>;
				trigger-sources = <&ovl1_mutex 23>;
			};

			ovl1_outproc4: outproc@1b0000 {
				compatible = "mediatek,mt8196-disp-outproc";
				reg = <0 0x1b0000 0 0x1000>;
				clocks = <&ovlsys1 CLK_OVL1_OVL_OUTPROC4>;
				trigger-sources = <&ovl1_mutex 24>;
			};

			ovl1_outproc5: outproc@1c0000 {
				compatible = "mediatek,mt8196-disp-outproc";
				reg = <0 0x1c0000 0 0x1000>;
				clocks = <&ovlsys1 CLK_OVL1_OVL_OUTPROC5>;
				trigger-sources = <&ovl1_mutex 25>;
			};

			ovl1_rsz0: resizer@1d0000 {
				compatible = "mediatek,mt8196-disp-rsz";
				reg = <0 0x1d0000 0 0x1000>;
				clocks = <&ovlsys1 CLK_OVL1_OVL_MDP_RSZ0>;
				power-domains = <&hpm_hwv MT8196_POWER_DOMAIN_OVL1_DORMANT>;
				trigger-sources = <&ovl1_mutex 26>;

				ports {
					#address-cells = <1>;
					#size-cells = <0>;

					port@0 {
						#address-cells = <1>;
						#size-cells = <0>;
						reg = <0>;

						ovl1_resizer0_in: endpoint@2 {
							reg = <2>;
							remote-endpoint = <&ovlsys1_ep_third>;
						};
					};

					port@1 {
						#address-cells = <1>;
						#size-cells = <0>;
						reg = <1>;

						ovl1_resizer0_out: endpoint@2 {
							reg = <2>;
							remote-endpoint = <&exdma1_2_in>;
						};
					};
				};
			};

			ovl1_rsz1: resizer@1e0000 {
				compatible = "mediatek,mt8196-disp-rsz";
				reg = <0 0x1e0000 0 0x1000>;
				clocks = <&ovlsys1 CLK_OVL1_OVL_MDP_RSZ1>;
				power-domains = <&hpm_hwv MT8196_POWER_DOMAIN_OVL1_DORMANT>;
				trigger-sources = <&ovl1_mutex 27>;
				status = "disabled";
			};
		};

		vdecsys_soc: clock-controller@3600f000 {
			compatible = "mediatek,mt8196-vdecsys-soc";
			reg = <0 0x3600f000 0 0x1000>;
			power-domains = <&hpm_hwv MT8196_POWER_DOMAIN_VDE0>;
			mediatek,hardware-voter = <&hfrpsys_hwv>;
			#clock-cells = <1>;
		};

		vdecsys1: clock-controller@3602f000 {
			compatible = "mediatek,mt8196-vdecsys";
			reg = <0 0x3602f000 0 0x1000>;
			power-domains = <&hpm_hwv MT8196_POWER_DOMAIN_VDE1>;
			mediatek,hardware-voter = <&hfrpsys_hwv>;
			#clock-cells = <1>;
		};

		vencsys0: clock-controller@38000000 {
			compatible = "mediatek,mt8196-vencsys";
			reg = <0 0x38000000 0 0x1000>;
			power-domains = <&hpm_hwv MT8196_POWER_DOMAIN_VEN0>;
			mediatek,hardware-voter = <&hfrpsys_hwv>;
			#clock-cells = <1>;
		};

		vencsys1: clock-controller@38800000 {
			compatible = "mediatek,mt8196-vencsys-c1";
			reg = <0 0x38800000 0 0x1000>;
			power-domains = <&hpm_hwv MT8196_POWER_DOMAIN_VEN1>;
			mediatek,hardware-voter = <&hfrpsys_hwv>;
			#clock-cells = <1>;
		};

		vencsys2: clock-controller@38c00000 {
			compatible = "mediatek,mt8196-vencsys-c2";
			reg = <0 0x38c00000 0 0x1000>;
			power-domains = <&hpm_hwv MT8196_POWER_DOMAIN_VEN2>;
			mediatek,hardware-voter = <&hfrpsys_hwv>;
			#clock-cells = <1>;
		};

		mdpsys0: clock-controller@3e000000 {
			compatible = "mediatek,mt8196-mdpsys0";
			reg = <0 0x3e000000 0 0x1000>;
			power-domains = <&hpm_hwv MT8196_POWER_DOMAIN_MML0_SHUTDOWN>;
			#clock-cells = <1>;
		};

		mdpsys1: clock-controller@3e400000 {
			compatible = "mediatek,mt8196-mdpsys1";
			reg = <0 0x3e400000 0 0x1000>;
			power-domains = <&hpm_hwv MT8196_POWER_DOMAIN_MML1_SHUTDOWN>;
			#clock-cells = <1>;
		};

		vdisp_ao: clock-controller@3e800000 {
			compatible = "mediatek,mt8196-vdisp-ao";
			reg = <0 0x3e800000 0 0x1000>;
			mediatek,hardware-voter = <&hfrpsys_hwv>;
			#clock-cells = <1>;
		};

		edp_tx: displayport-controller@3ec42000 {
			compatible = "mediatek,mt8196-edp-tx";
			reg = <0 0x3ec42000 0 0x3000>,  <0 0x3ec40000 0 0x1000>;
			phys = <&edp_phy>;
			power-domains = <&hpm MT8196_POWER_DOMAIN_EDPTX>;
			max-linkrate-mhz = <8100>;
			interrupts = <GIC_SPI 448 IRQ_TYPE_LEVEL_HIGH 0>;
			status = "disabled";
		};
	};

	sound: mt8196-sound {
		mediatek,platform = <&afe>;
		status = "disabled";
	};

	thermal_zones: thermal-zones {
		cpu6-0-thermal {
			polling-delay = <1000>;
			thermal-sensors = <&lvts_mcu MT8196_MCU_MEDIUM_CPU6_0>;
			trips {
				cpu6_0_crit: trip-crit {
					temperature = <118800>;
					hysteresis = <2000>;
					type = "critical";
				};
			};
		};

		cpu6-1-thermal {
			polling-delay = <1000>;
			thermal-sensors = <&lvts_mcu MT8196_MCU_MEDIUM_CPU6_1>;
			trips {
				cpu6_1_crit: trip-crit {
					temperature = <118800>;
					hysteresis = <2000>;
					type = "critical";
				};
			};
		};

		dsu2-thermal {
			polling-delay = <1000>;
			thermal-sensors = <&lvts_mcu MT8196_MCU_DSU2>;
			trips {
				dsu2_crit: trip-crit {
					temperature = <118800>;
					hysteresis = <2000>;
					type = "critical";
				};
			};
		};

		dsu3-thermal {
			polling-delay = <1000>;
			thermal-sensors = <&lvts_mcu MT8196_MCU_DSU3>;
			trips {
				dsu3_crit: trip-crit {
					temperature = <118800>;
					hysteresis = <2000>;
					type = "critical";
				};
			};
		};

		cpu3-thermal {
			polling-delay = <1000>;
			thermal-sensors = <&lvts_mcu MT8196_MCU_LITTLE_CPU3>;
			trips {
				cpu3_crit: trip-crit {
					temperature = <118800>;
					hysteresis = <2000>;
					type = "critical";
				};
			};
		};

		cpu0-thermal {
			polling-delay = <1000>;
			thermal-sensors = <&lvts_mcu MT8196_MCU_LITTLE_CPU0>;
			trips {
				cpu0_crit: trip-crit {
					temperature = <118800>;
					hysteresis = <2000>;
					type = "critical";
				};
			};
		};

		cpu1-thermal {
			polling-delay = <1000>;
			thermal-sensors = <&lvts_mcu MT8196_MCU_LITTLE_CPU1>;
			trips {
				cpu1_crit: trip-crit {
					temperature = <118800>;
					hysteresis = <2000>;
					type = "critical";
				};
			};
		};

		cpu2-thermal {
			polling-delay = <1000>;
			thermal-sensors = <&lvts_mcu MT8196_MCU_LITTLE_CPU2>;
			trips {
				cpu2_crit: trip-crit {
					temperature = <118800>;
					hysteresis = <2000>;
					type = "critical";
				};
			};
		};

		cpu4-0-thermal {
			polling-delay = <1000>;
			thermal-sensors = <&lvts_mcu MT8196_MCU_MEDIUM_CPU4_0>;
			trips {
				cpu4_0_crit: trip-crit {
					temperature = <118800>;
					hysteresis = <2000>;
					type = "critical";
				};
			};
		};

		cpu4-1-thermal {
			polling-delay = <1000>;
			thermal-sensors = <&lvts_mcu MT8196_MCU_MEDIUM_CPU4_1>;
			trips {
				cpu4_1_crit: trip-crit {
					temperature = <118800>;
					hysteresis = <2000>;
					type = "critical";
				};
			};
		};

		cpu5-0-thermal {
			polling-delay = <1000>;
			thermal-sensors = <&lvts_mcu MT8196_MCU_MEDIUM_CPU5_0>;
			trips {
				cpu5_0_crit: trip-crit {
					temperature = <118800>;
					hysteresis = <2000>;
					type = "critical";
				};
			};
		};

		cpu5-1-thermal {
			polling-delay = <1000>;
			thermal-sensors = <&lvts_mcu MT8196_MCU_MEDIUM_CPU5_1>;
			trips {
				cpu5_1_crit: trip-crit {
					temperature = <118800>;
					hysteresis = <2000>;
					type = "critical";
				};
			};
		};

		dsu0-thermal {
			polling-delay = <1000>;
			thermal-sensors = <&lvts_mcu MT8196_MCU_DSU0>;
			trips {
				dsu0_crit: trip-crit {
					temperature = <118800>;
					hysteresis = <2000>;
					type = "critical";
				};
			};
		};

		dsu1-thermal {
			polling-delay = <1000>;
			thermal-sensors = <&lvts_mcu MT8196_MCU_DSU1>;
			trips {
				dsu1_crit: trip-crit {
					temperature = <118800>;
					hysteresis = <2000>;
					type = "critical";
				};
			};
		};

		cpu7-0-thermal {
			polling-delay = <1000>;
			thermal-sensors = <&lvts_mcu MT8196_MCU_BIG_CPU7_0>;
			trips {
				cpu7_0_crit: trip-crit {
					temperature = <118800>;
					hysteresis = <2000>;
					type = "critical";
				};
			};
		};

		cpu7-1-thermal {
			polling-delay = <1000>;
			thermal-sensors = <&lvts_mcu MT8196_MCU_BIG_CPU7_1>;
			trips {
				cpu7_1_crit: trip-crit {
					temperature = <118800>;
					hysteresis = <2000>;
					type = "critical";
				};
			};
		};

		soc-top0-thermal {
			polling-delay = <1000>;
			thermal-sensors = <&lvts_ap MT8196_AP_TOP0>;

			trips {
				soc_top0_crit: trip-crit {
					temperature = <118800>;
					hysteresis = <2000>;
					type = "critical";
				};
			};
		};

		soc-top1-thermal {
			polling-delay = <1000>;
			thermal-sensors = <&lvts_ap MT8196_AP_TOP1>;
			trips {
				soc_top1_crit: trip-crit {
					temperature = <118800>;
					hysteresis = <2000>;
					type = "critical";
				};
			};
		};

		soc-top2-thermal {
			polling-delay = <1000>;
			thermal-sensors = <&lvts_ap MT8196_AP_TOP2>;
			trips {
				soc_top2_crit: trip-crit {
					temperature = <118800>;
					hysteresis = <2000>;
					type = "critical";
				};
			};
		};

		soc-top3-thermal {
			polling-delay = <1000>;
			thermal-sensors = <&lvts_ap MT8196_AP_TOP3>;
			trips {
				soc_top3_crit: trip-crit {
					temperature = <118800>;
					hysteresis = <2000>;
					type = "critical";
				};
			};
		};

		soc-bot0-thermal {
			polling-delay = <1000>;
			thermal-sensors = <&lvts_ap MT8196_AP_BOT0>;
			trips {
				soc_bot0_crit: trip-crit {
					temperature = <118800>;
					hysteresis = <2000>;
					type = "critical";
				};
			};
		};

		soc-bot1-thermal {
			polling-delay = <1000>;
			thermal-sensors = <&lvts_ap MT8196_AP_BOT1>;
			trips {
				soc_bot1_crit: trip-crit {
					temperature = <118800>;
					hysteresis = <2000>;
					type = "critical";
				};
			};
		};

		soc-bot2-thermal {
			polling-delay = <1000>;
			thermal-sensors = <&lvts_ap MT8196_AP_BOT2>;
			trips {
				soc_bot2_crit: trip-crit {
					temperature = <118800>;
					hysteresis = <2000>;
					type = "critical";
				};
			};
		};

		soc-bot3-thermal {
			polling-delay = <1000>;
			thermal-sensors = <&lvts_ap MT8196_AP_BOT3>;
			trips {
				soc_bot3_crit: trip-crit {
					temperature = <118800>;
					hysteresis = <2000>;
					type = "critical";
				};
			};
		};
	};

	timer {
		compatible = "arm,armv8-timer";
		interrupt-parent = <&gic>;
		interrupts = <GIC_PPI 13 IRQ_TYPE_LEVEL_HIGH 0>,
			     <GIC_PPI 14 IRQ_TYPE_LEVEL_HIGH 0>,
			     <GIC_PPI 11 IRQ_TYPE_LEVEL_HIGH 0>,
			     <GIC_PPI 10 IRQ_TYPE_LEVEL_HIGH 0>;
		clock-frequency = <13000000>;
	};
};

/* High Frame Rate Processor System Controller (HFRPSYS) Power Domains */
&hpm_hwv {
	power-domain@MT8196_POWER_DOMAIN_DSI_PHY0 {
		reg = <MT8196_POWER_DOMAIN_DSI_PHY0>;
		#power-domain-cells = <0>;
	};

	power-domain@MT8196_POWER_DOMAIN_DSI_PHY1 {
		reg = <MT8196_POWER_DOMAIN_DSI_PHY1>;
		#power-domain-cells = <0>;
	};

	power-domain@MT8196_POWER_DOMAIN_DSI_PHY2 {
		reg = <MT8196_POWER_DOMAIN_DSI_PHY2>;
		#power-domain-cells = <0>;
	};

	power-domain@MT8196_POWER_DOMAIN_MM_INFRA_AO {
		reg = <MT8196_POWER_DOMAIN_MM_INFRA_AO>;
		#address-cells = <1>;
		#size-cells = <0>;
		#power-domain-cells = <0>;

		power-domain@MT8196_POWER_DOMAIN_MM_INFRA0 {
			reg = <MT8196_POWER_DOMAIN_MM_INFRA0>;
			#address-cells = <1>;
			#size-cells = <0>;
			#power-domain-cells = <0>;

			power-domain@MT8196_POWER_DOMAIN_MM_INFRA1 {
				reg = <MT8196_POWER_DOMAIN_MM_INFRA1>;
				#address-cells = <1>;
				#size-cells = <0>;
				#power-domain-cells = <0>;

				power-domain@MT8196_POWER_DOMAIN_CSI_BS_RX {
					reg = <MT8196_POWER_DOMAIN_CSI_BS_RX>;
					#power-domain-cells = <0>;
				};

				power-domain@MT8196_POWER_DOMAIN_CSI_LS_RX {
					reg = <MT8196_POWER_DOMAIN_CSI_LS_RX>;
					#power-domain-cells = <0>;
				};

				power-domain@MT8196_POWER_DOMAIN_DISP_VCORE {
					reg = <MT8196_POWER_DOMAIN_DISP_VCORE>;
					#address-cells = <1>;
					#size-cells = <0>;
					#power-domain-cells = <0>;

					power-domain@MT8196_POWER_DOMAIN_DIS0_DORMANT {
						reg = <MT8196_POWER_DOMAIN_DIS0_DORMANT>;
						clocks = <&vdisp_ao CLK_MM_V_DISP_VDISP_AO_CONFIG>,
							 <&vdisp_ao CLK_MM_V_DISP_DPC>;
						clock-names = "cfg", "dpc";
						#power-domain-cells = <0>;
					};

					power-domain@MT8196_POWER_DOMAIN_DIS1_DORMANT {
						reg = <MT8196_POWER_DOMAIN_DIS1_DORMANT>;
						clocks = <&vdisp_ao CLK_MM_V_DISP_VDISP_AO_CONFIG>,
							 <&vdisp_ao CLK_MM_V_DISP_DPC>;
						clock-names = "cfg", "dpc";
						#power-domain-cells = <0>;
					};

					power-domain@MT8196_POWER_DOMAIN_DISP_EDPTX_DORMANT {
						reg = <MT8196_POWER_DOMAIN_DISP_EDPTX_DORMANT>;
						clocks = <&vdisp_ao CLK_MM_V_DISP_VDISP_AO_CONFIG>,
							 <&vdisp_ao CLK_MM_V_DISP_DPC>;
						clock-names = "cfg", "dpc";
						#power-domain-cells = <0>;
					};

					power-domain@MT8196_POWER_DOMAIN_DISP_DPTX_DORMANT {
						reg = <MT8196_POWER_DOMAIN_DISP_DPTX_DORMANT>;
						clocks = <&vdisp_ao CLK_MM_V_DISP_VDISP_AO_CONFIG>,
							 <&vdisp_ao CLK_MM_V_DISP_DPC>;
						clock-names = "cfg", "dpc";
						#power-domain-cells = <0>;
					};

					power-domain@MT8196_POWER_DOMAIN_OVL0_DORMANT {
						reg = <MT8196_POWER_DOMAIN_OVL0_DORMANT>;
						clocks = <&vdisp_ao CLK_MM_V_DISP_VDISP_AO_CONFIG>,
							 <&vdisp_ao CLK_MM_V_DISP_DPC>;
						clock-names = "cfg", "dpc";
						#power-domain-cells = <0>;
					};

					power-domain@MT8196_POWER_DOMAIN_OVL1_DORMANT {
						reg = <MT8196_POWER_DOMAIN_OVL1_DORMANT>;
						clocks = <&vdisp_ao CLK_MM_V_DISP_VDISP_AO_CONFIG>,
							 <&vdisp_ao CLK_MM_V_DISP_DPC>;
						clock-names = "cfg", "dpc";
						#power-domain-cells = <0>;
					};

					power-domain@MT8196_POWER_DOMAIN_MML0_SHUTDOWN {
						reg = <MT8196_POWER_DOMAIN_MML0_SHUTDOWN>;
						#power-domain-cells = <0>;
					};

					power-domain@MT8196_POWER_DOMAIN_MML1_SHUTDOWN {
						reg = <MT8196_POWER_DOMAIN_MML1_SHUTDOWN>;
						#power-domain-cells = <0>;
					};
				};

				power-domain@MT8196_POWER_DOMAIN_VDE_VCORE0 {
					reg = <MT8196_POWER_DOMAIN_VDE_VCORE0>;
					#address-cells = <1>;
					#size-cells = <0>;
					#power-domain-cells = <0>;

					power-domain@MT8196_POWER_DOMAIN_VDE0 {
						reg = <MT8196_POWER_DOMAIN_VDE0>;
						#power-domain-cells = <0>;
					};

					power-domain@MT8196_POWER_DOMAIN_VDE1 {
						reg = <MT8196_POWER_DOMAIN_VDE1>;
						#power-domain-cells = <0>;
					};
				};

				power-domain@MT8196_POWER_DOMAIN_VEN0 {
					reg = <MT8196_POWER_DOMAIN_VEN0>;
					#address-cells = <1>;
					#size-cells = <0>;
					#power-domain-cells = <0>;

					power-domain@MT8196_POWER_DOMAIN_VEN1 {
						reg = <MT8196_POWER_DOMAIN_VEN1>;
						#address-cells = <1>;
						#size-cells = <0>;
						#power-domain-cells = <0>;

						power-domain@MT8196_POWER_DOMAIN_VEN2 {
							reg = <MT8196_POWER_DOMAIN_VEN2>;
							#power-domain-cells = <0>;
						};
					};
				};
			};
		};
	};
};

#include "mt8196-downstream.dtsi"
#include "mt8196-iommu.dtsi"
